VERSION"HIPBNYYYYYYYYYYYYYYYYYYYYYYYYYYYNNNNNNNNNN/4/%%%/4/'%**4NNN///"

NS_ :

BS_:

BU_: RTRange

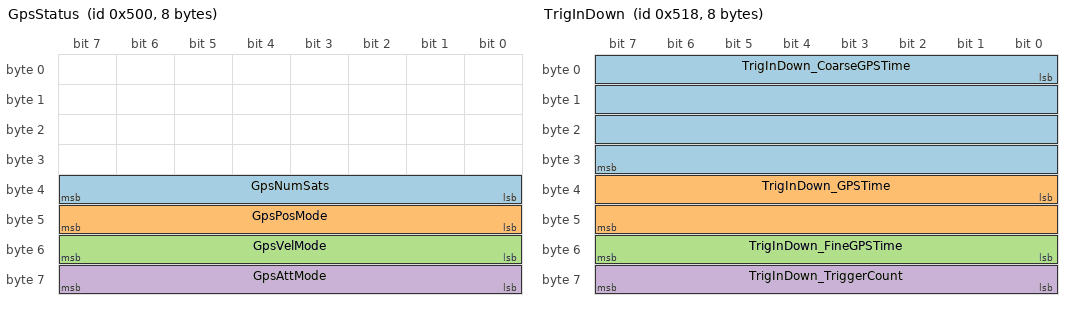
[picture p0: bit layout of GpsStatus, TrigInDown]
BO_ 1280 GpsStatus: 8  RT3000
 SG_ GpsNumSats : 32|8@1+ (1,0) [0|0] "" Vector__XXX
 SG_ GpsPosMode : 40|8@1+ (1,0) [0|0] "" Vector__XXX
 SG_ GpsVelMode : 48|8@1+ (1,0) [0|0] "" Vector__XXX
 SG_ GpsAttMode : 56|8@1+ (1,0) [0|0] "" Vector__XXX

BO_ 1283 PosNEDStdev: 8  RT3000
 SG_ PosNorthStdev : 0|16@1+ (0.001,0) [0|65.535] "m" Vector__XXX
 SG_ PosEastStdev : 16|16@1+ (0.001,0) [0|65.535] "m" Vector__XXX
 SG_ PosDownStdev : 32|16@1+ (0.001,0) [0|65.535] "m" Vector__XXX

BO_ 1284 VelNEDStdev: 8  RT3000
 SG_ VelNorthStdev : 0|16@1+ (0.001,0) [0|65.535] "m/s" Vector__XXX
 SG_ VelEastStdev : 16|16@1+ (0.001,0) [0|65.535] "m/s" Vector__XXX
 SG_ VelDownStdev : 32|16@1+ (0.001,0) [0|65.535] "m/s" Vector__XXX

BO_ 1285 AngleStdev: 8  RT3000
 SG_ AngleHeadingStdev : 0|16@1+ (0.0005729577951,0) [0|37.548789102] "°" Vector__XXX
 SG_ AnglePitchStdev : 16|16@1+ (0.0005729577951,0) [0|37.548789102] "°" Vector__XXX
 SG_ AngleRollStdev : 32|16@1+ (0.0005729577951,0) [0|37.548789102] "°" Vector__XXX

BO_ 1286 GyroBias: 8  RT3000
 SG_ GyroBias1 : 0|16@1- (0.0002864788976,0) [-9.387340515|9.387054037] "°" Vector__XXX
 SG_ GyroBias2 : 16|16@1- (0.0002864788976,0) [-9.387340515|9.387054037] "°" Vector__XXX
 SG_ GyroBias3 : 32|16@1- (0.0002864788976,0) [-9.387340515|9.387054037] "°" Vector__XXX

BO_ 1287 AccelBias: 8  RT3000
 SG_ AccelBias1 : 0|16@1- (0.0001,0) [-3.2768|3.2767] "m/s²" Vector__XXX
 SG_ AccelBias2 : 16|16@1- (0.0001,0) [-3.2768|3.2767] "m/s²" Vector__XXX
 SG_ AccelBias3 : 32|16@1- (0.0001,0) [-3.2768|3.2767] "m/s²" Vector__XXX

BO_ 1288 GyroSf: 8  RT3000
 SG_ GyroSf1 : 0|16@1- (1,0) [-32768|32767] "ppm" Vector__XXX
 SG_ GyroSf2 : 16|16@1- (1,0) [-32768|32767] "ppm" Vector__XXX
 SG_ GyroSf3 : 32|16@1- (1,0) [-32768|32767] "ppm" Vector__XXX

BO_ 1289 GyroBiasStdev: 8  RT3000
 SG_ GyroBias1Stdev  : 0|16@1+ (5.729577951E-005,0) [0|3.7548789102] "°/s" Vector__XXX
 SG_ GyroBias2Stdev  : 16|16@1+ (5.729577951E-005,0) [0|3.7548789102] "°/s" Vector__XXX
 SG_ GyroBias3Stdev  : 32|16@1+ (5.729577951E-005,0) [0|3.7548789102] "°/s" Vector__XXX

BO_ 1290 AccelBiasStdev: 8  RT3000
 SG_ AccelBias1Stdev : 0|16@1+ (1E-005,0) [0|0.65535] "m/s²" Vector__XXX
 SG_ AccelBias2Stdev : 16|16@1+ (1E-005,0) [0|0.65535] "m/s²" Vector__XXX
 SG_ AccelBias3Stdev : 32|16@1+ (1E-005,0) [0|0.65535] "m/s²" Vector__XXX

BO_ 1291 GyroSfStdev: 8  RT3000
 SG_ GyroSf1Stdev : 0|16@1+ (1,0) [0|65535] "ppm" Vector__XXX
 SG_ GyroSf2Stdev : 16|16@1+ (1,0) [0|65535] "ppm" Vector__XXX
 SG_ GyroSf3Stdev : 32|16@1+ (1,0) [0|65535] "ppm" Vector__XXX

BO_ 1292 GpsAntOffset: 8  RT3000
 SG_ GpsAntX : 0|16@1- (0.001,0) [-32.768|32.767] "m" Vector__XXX
 SG_ GpsAntY : 16|16@1- (0.001,0) [-32.768|32.767] "m" Vector__XXX
 SG_ GpsAntZ : 32|16@1- (0.001,0) [-32.768|32.767] "m" Vector__XXX

BO_ 1293 GpsAntAngles: 8  RT3000
 SG_ GpsAntHeading : 0|16@1- (0.005729578,0) [-187.7468103084|187.741080735] "°" Vector__XXX
 SG_ GpsAntPitch : 16|16@1- (0.005729578,0) [-187.7468103084|187.741080735] "°" Vector__XXX

BO_ 1294 GPSAntStdev: 8  RT3000
 SG_ GpsAntXStdev  : 0|16@1+ (0.0001,0) [0|6.5535] "m" Vector__XXX
 SG_ GpsAntYStdev  : 16|16@1+ (0.0001,0) [0|6.5535] "m" Vector__XXX
 SG_ GpsAntZStdev  : 32|16@1+ (0.0001,0) [0|6.5535] "m" Vector__XXX

BO_ 1295 GPSAntAngleStdev: 8  RT3000
 SG_ GpsAntHeadingStdev : 0|16@1+ (0.0005729577951,0) [0|37.548789102] "°" Vector__XXX
 SG_ GpsAntPitchStdev : 16|16@1+ (0.0005729577951,0) [0|37.548789102] "°" Vector__XXX

BO_ 1300 GpsDiffAge: 8  RT3000
 SG_ GpsDiffAge : 0|16@1+ (0.01,0) [0|655.35] "s" Vector__XXX

BO_ 1304 TrigInDown: 8  RT3000
 SG_ TrigInDown_CoarseGPSTime : 0|32@1+ (1,0) [0|4294967296]"minute" Vector__XXX
 SG_ TrigInDown_GPSTime : 32|16@1+ (0.001,0) [0|65.536]"s" Vector__XXX
 SG_ TrigInDown_FineGPSTime : 48|8@1- (0.004,0) [-0.512|0.512]"ms" Vector__XXX
 SG_ TrigInDown_TriggerCount : 56|8@1+ (1,0) [0|256]"" Vector__XXX

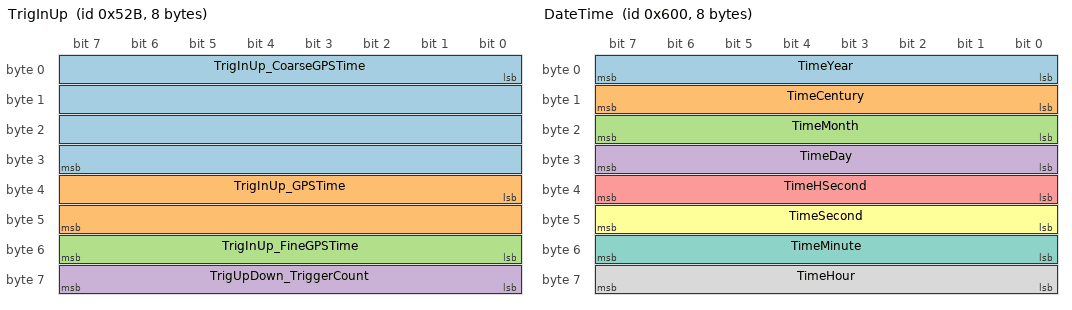
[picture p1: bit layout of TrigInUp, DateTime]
BO_ 1323 TrigInUp: 8  RT3000
 SG_ TrigInUp_CoarseGPSTime : 0|32@1+ (1,0) [0|4294967296]"minute" Vector__XXX
 SG_ TrigInUp_GPSTime : 32|16@1+ (0.001,0) [0|65.536]"s" Vector__XXX
 SG_ TrigInUp_FineGPSTime : 48|8@1- (0.004,0) [-0.512|0.512]"ms" Vector__XXX
 SG_ TrigUpDown_TriggerCount : 56|8@1+ (1,0) [0|256]"" Vector__XXX

BO_ 1325 WheelSpeedStatus: 8  RT3000
 SG_ WSpeedCount : 0|32@1+ (1,0) [0|4294967296] "" Vector__XXX
 SG_ WSpeedGPSTime : 32|16@1+ (0.001,0) [0|65.536]"s" Vector__XXX
 SG_ WSpeedChangeTime : 48|8@1+ (0.1,0) [0|25.6]"s" Vector__XXX

BO_ 1328 UndulationDOP: 8  RT3000
 SG_ Undulation : 0|16@1- (0.005,0) [-163.84|163.835] "m" Vector__XXX
 SG_ HDOP : 16|8@1+ (0.1,0) [0|25.5] "" Vector__XXX
 SG_ PDOP : 24|8@1+ (0.1,0) [0|25.5] "" Vector__XXX

BO_ 1329 OmniStarTracking: 8  RT3000
 SG_ OmniSatFreq : 0|16@1+ (0.001,1520) [1520|1585.535] "MHz" Vector__XXX
 SG_ OmniSNR : 16|8@1+ (0.2,0) [0|51] "dB" Vector__XXX
 SG_ OmniTrackTime : 24|8@1+ (1,0) [0|255] "s" Vector__XXX

BO_ 1343 AngAccFilt: 8  RT3000

BO_ 1536 DateTime: 8  RT3000
 SG_ TimeYear : 0|8@1+ (1,0) [0|100] "" Vector__XXX
 SG_ TimeCentury : 8|8@1+ (1,0) [0|0] "" Vector__XXX
 SG_ TimeMonth : 16|8@1+ (1,0) [0|12] "" Vector__XXX
 SG_ TimeDay : 24|8@1+ (1,0) [0|31] "" Vector__XXX
 SG_ TimeHSecond : 32|8@1+ (0.01,0) [0|1.00] "s" Vector__XXX
 SG_ TimeSecond : 40|8@1+ (1,0) [0|60] "s" Vector__XXX
 SG_ TimeMinute : 48|8@1+ (1,0) [0|60] "min" Vector__XXX
 SG_ TimeHour : 56|8@1+ (1,0) [0|24] "hr" Vector__XXX

BO_ 1537 LatitudeLongitude: 8  RT3000
 SG_ PosLat : 0|32@1- (1E-007,0) [-214.7483648|214.7483647] "°" Vector__XXX
 SG_ PosLon : 32|32@1- (1E-007,0) [-214.7483648|214.7483647] "°" Vector__XXX

BO_ 1538 Altitude: 4  RT3000
 SG_ PosAlt : 0|32@1- (0.001,0) [-2147483.648|2147483.647] "m" Vector__XXX

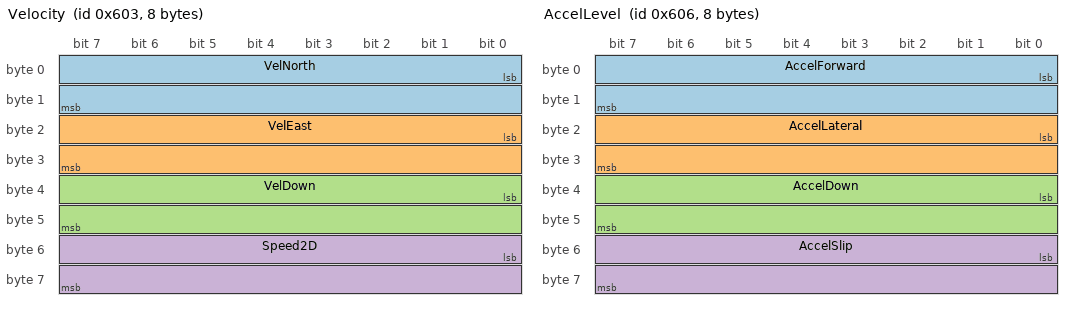
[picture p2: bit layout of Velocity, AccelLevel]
BO_ 1539 Velocity: 8  RT3000
 SG_ VelNorth : 0|16@1- (0.01,0) [-327.68|327.67] "m/s" Vector__XXX
 SG_ VelEast : 16|16@1- (0.01,0) [-327.68|327.67] "m/s" Vector__XXX
 SG_ VelDown : 32|16@1- (0.01,0) [-327.68|327.67] "m/s" Vector__XXX
 SG_ Speed2D : 48|16@1+ (0.01,0) [0|655.35] "m/s" Vector__XXX

BO_ 1540 VelocityLevel: 4  RT3000
 SG_ VelForward : 0|16@1- (0.01,0) [-327.68|327.67] "m/s" Vector__XXX
 SG_ VelLateral : 16|16@1- (0.01,0) [-327.68|327.67] "m/s" Vector__XXX

BO_ 1541 AccelVehicle: 6  RT3000
 SG_ AccelX : 0|16@1- (0.01,0) [-327.68|327.67] "m/s²" Vector__XXX
 SG_ AccelY : 16|16@1- (0.01,0) [-327.68|327.67] "m/s²" Vector__XXX
 SG_ AccelZ : 32|16@1- (0.01,0) [-327.68|327.67] "m/s²" Vector__XXX

BO_ 1542 AccelLevel: 8  RT3000
 SG_ AccelForward : 0|16@1- (0.01,0) [-327.68|327.67] "m/s²" Vector__XXX
 SG_ AccelLateral : 16|16@1- (0.01,0) [-327.68|327.67] "m/s²" Vector__XXX
 SG_ AccelDown : 32|16@1- (0.01,0) [-327.68|327.67] "m/s²" Vector__XXX
 SG_ AccelSlip : 48|16@1- (0.01,0) [-327.68|327.67] "m/s²" Vector__XXX

BO_ 1543 HeadingPitchRoll: 6  RT3000
 SG_ AngleHeading : 0|16@1+ (0.01,0) [0|655.35] "°" Vector__XXX
 SG_ AnglePitch : 16|16@1- (0.01,0) [-327.68|327.67] "°" Vector__XXX
 SG_ AngleRoll : 32|16@1- (0.01,0) [-327.68|327.67] "°" Vector__XXX

BO_ 1544 RateVehicle: 6  RT3000
 SG_ AngRateX : 0|16@1- (0.01,0) [-327.68|327.67] "°/s" Vector__XXX
 SG_ AngRateY : 16|16@1- (0.01,0) [-327.68|327.67] "°/s" Vector__XXX
 SG_ AngRateZ : 32|16@1- (0.01,0) [-327.68|327.67] "°/s" Vector__XXX

BO_ 1545 RateLevel: 6  RT3000
 SG_ AngRateForward : 0|16@1- (0.01,0) [-327.68|327.67] "°/s" Vector__XXX
 SG_ AngRateLateral : 16|16@1- (0.01,0) [-327.68|327.67] "°/s" Vector__XXX
 SG_ AngRateDown : 32|16@1- (0.01,0) [-327.68|327.67] "°/s" Vector__XXX

BO_ 1546 TrackSlipCurvature: 6  RT3000
 SG_ AngleTrack : 0|16@1+ (0.01,0) [0|655.35] "°" Vector__XXX
 SG_ AngleSlip : 16|16@1- (0.01,0) [-327.68|327.67] "°" Vector__XXX
 SG_ Curvature : 32|16@1- (0.0001,0) [-3.2768|3.2767] "1/m" Vector__XXX

BO_ 1547 Distance: 8  RT3000
 SG_ DistanceWithHold : 0|32@1+ (0.001,0) [0|4294967.295] "m" Vector__XXX
 SG_ Distance : 32|32@1+ (0.001,0) [0|4294967.295] "m" Vector__XXX

BO_ 1548 PosLocal: 8  RT3000
 SG_ PosLocalX : 0|32@1- (0.0001,0) [-214748.3648|214748.3647] "m" Vector__XXX
 SG_ PosLocalY : 32|32@1- (0.0001,0) [-214748.3648|214748.3647] "m" Vector__XXX

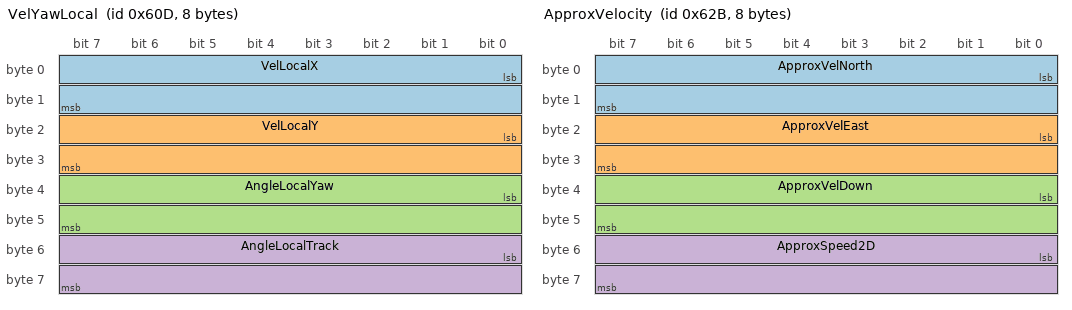
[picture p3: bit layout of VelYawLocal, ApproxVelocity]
BO_ 1549 VelYawLocal: 8  RT3000
 SG_ VelLocalX : 0|16@1- (0.01,0) [-327.68|327.67] "m/s" Vector__XXX
 SG_ VelLocalY : 16|16@1- (0.01,0) [-327.68|327.67] "m/s" Vector__XXX
 SG_ AngleLocalYaw : 32|16@1- (0.01,0) [-327.68|327.67] "°" Vector__XXX
 SG_ AngleLocalTrack : 48|16@1- (0.01,0) [-327.68|327.67] "°" Vector__XXX

BO_ 1550 AngAccelVehicle: 6  RT3000
 SG_ AngAccelX : 0|16@1- (0.1,0) [-3276.8|3276.7] "°/s²" Vector__XXX
 SG_ AngAccelY : 16|16@1- (0.1,0) [-3276.8|3276.7] "°/s²" Vector__XXX
 SG_ AngAccelZ : 32|16@1- (0.1,0) [-3276.8|3276.7] "°/s²" Vector__XXX

BO_ 1551 AngAccelLevel: 6  RT3000
 SG_ AngAccelForward : 0|16@1- (0.1,0) [-3276.8|3276.7] "°/s²" Vector__XXX
 SG_ AngAccelLateral : 16|16@1- (0.1,0) [-3276.8|3276.7] "°/s²" Vector__XXX
 SG_ AngAccelDown : 32|16@1- (0.1,0) [-3276.8|3276.7] "°/s²" Vector__XXX

BO_ 1568 TrackSlipCurvaturePoint1: 8  RT3000
 SG_ AngleTrackPoint1 : 0|16@1+ (0.01,0) [0|655.35] "°" Vector__XXX
 SG_ AngleSlipPoint1 : 16|16@1- (0.01,0) [-327.68|327.67] "°" Vector__XXX
 SG_ CurvaturePoint1 : 32|16@1- (0.0001,0) [-3.2768|3.2767] "1/m" Vector__XXX

BO_ 1569 TrackSlipCurvaturePoint2: 8  RT3000
 SG_ AngleTrackPoint2 : 0|16@1+ (0.01,0) [0|655.35] "°" Vector__XXX
 SG_ AngleSlipPoint2 : 16|16@1- (0.01,0) [-327.68|327.67] "°" Vector__XXX
 SG_ CurvaturePoint2 : 32|16@1- (0.0001,0) [-3.2768|3.2767] "1/m" Vector__XXX

BO_ 1570 TrackSlipCurvaturePoint3: 8  RT3000
 SG_ AngleTrackPoint3 : 0|16@1+ (0.01,0) [0|655.35] "°" Vector__XXX
 SG_ AngleSlipPoint3 : 16|16@1- (0.01,0) [-327.68|327.67] "°" Vector__XXX
 SG_ CurvaturePoint3 : 32|16@1- (0.0001,0) [-3.2768|3.2767] "1/m" Vector__XXX

BO_ 1571 TrackSlipCurvaturePoint4: 8  RT3000
 SG_ AngleTrackPoint4 : 0|16@1+ (0.01,0) [0|655.35] "°" Vector__XXX
 SG_ AngleSlipPoint4 : 16|16@1- (0.01,0) [-327.68|327.67] "°" Vector__XXX
 SG_ CurvaturePoint4 : 32|16@1- (0.0001,0) [-3.2768|3.2767] "1/m" Vector__XXX

BO_ 1572 HeadingPitchRollFromSurf: 6  RT3000
 SG_ AngleHeadingFromSurf : 0|16@1+ (0.01,0) [0|655.35] "°" Vector__XXX
 SG_ AnglePitchFromSurf : 16|16@1- (0.01,0) [-327.68|327.67] "°" Vector__XXX
 SG_ AngleRollFromSurf : 32|16@1- (0.01,0) [-327.68|327.67] "°" Vector__XXX

BO_ 1573 TrackSlipCurvaturePoint5: 8  RT3000
 SG_ AngleTrackPoint5 : 0|16@1+ (0.01,0) [0|655.35] "°" Vector__XXX
 SG_ AngleSlipPoint5 : 16|16@1- (0.01,0) [-327.68|327.67] "°" Vector__XXX
 SG_ CurvaturePoint5 : 32|16@1- (0.0001,0) [-3.2768|3.2767] "1/m" Vector__XXX

BO_ 1574 TrackSlipCurvaturePoint6: 8  RT3000
 SG_ AngleTrackPoint6 : 0|16@1+ (0.01,0) [0|655.35] "°" Vector__XXX
 SG_ AngleSlipPoint6 : 16|16@1- (0.01,0) [-327.68|327.67] "°" Vector__XXX
 SG_ CurvaturePoint6 : 32|16@1- (0.0001,0) [-3.2768|3.2767] "1/m" Vector__XXX

BO_ 1575 TrackSlipCurvaturePoint7: 8  RT3000
 SG_ AngleTrackPoint7 : 0|16@1+ (0.01,0) [0|655.35] "°" Vector__XXX
 SG_ AngleSlipPoint7 : 16|16@1- (0.01,0) [-327.68|327.67] "°" Vector__XXX
 SG_ CurvaturePoint7 : 32|16@1- (0.0001,0) [-3.2768|3.2767] "1/m" Vector__XXX

BO_ 1576 TrackSlipCurvaturePoint8: 8  RT3000
 SG_ AngleTrackPoint8 : 0|16@1+ (0.01,0) [0|655.35] "°" Vector__XXX
 SG_ AngleSlipPoint8 : 16|16@1- (0.01,0) [-327.68|327.67] "°" Vector__XXX
 SG_ CurvaturePoint8 : 32|16@1- (0.0001,0) [-3.2768|3.2767] "1/m" Vector__XXX

BO_ 1577 ApproxLatitudeLongitude: 8  RT3000
 SG_ ApproxPosLat : 0|32@1- (1E-007,0) [-214.7483648|214.7483647] "°" Vector__XXX
 SG_ ApproxPosLon : 32|32@1- (1E-007,0) [-214.7483648|214.7483647] "°" Vector__XXX

BO_ 1578 ApproxAltitude: 4  RT3000
 SG_ ApproxPosAlt : 0|32@1- (0.001,0) [-2147483.648|2147483.647] "m" Vector__XXX

BO_ 1579 ApproxVelocity: 8  RT3000
 SG_ ApproxVelNorth : 0|16@1- (0.01,0) [-327.68|327.67] "m/s" Vector__XXX
 SG_ ApproxVelEast : 16|16@1- (0.01,0) [-327.68|327.67] "m/s" Vector__XXX
 SG_ ApproxVelDown : 32|16@1- (0.01,0) [-327.68|327.67] "m/s" Vector__XXX
 SG_ ApproxSpeed2D : 48|16@1+ (0.01,0) [0|655.35] "m/s" Vector__XXX

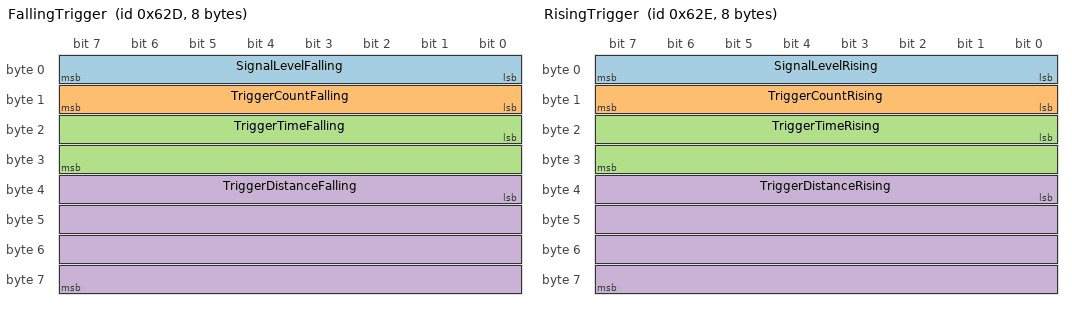
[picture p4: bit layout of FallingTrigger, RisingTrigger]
BO_ 1581 FallingTrigger: 8  RT3000
 SG_ SignalLevelFalling : 0|8 @1+ (1,0) [0|255] "" Vector__XXX
 SG_ TriggerCountFalling : 8|8 @1+ (1,0) [0|255] "" Vector__XXX
 SG_ TriggerTimeFalling : 16|16 @1+ (0.0002,0) [0|13.1072] "s" Vector__XXX
 SG_ TriggerDistanceFalling : 32|32 @1+ (0.001,0) [0|4294967.295] "m" Vector__XXX

BO_ 1582 RisingTrigger: 8  RT3000
 SG_ SignalLevelRising : 0|8 @1+ (1,0) [0|255] "" Vector__XXX
 SG_ TriggerCountRising : 8|8 @1+ (1,0) [0|255] "" Vector__XXX
 SG_ TriggerTimeRising : 16|16 @1+ (0.0002,0) [0|13.1072] "s" Vector__XXX
 SG_ TriggerDistanceRising : 32|32 @1+ (0.001,0) [0|4294967.295] "m" Vector__XXX

BO_ 1968  RangeForward: 8 RTRange
SG_ RangePosForward:                 0|32@1-  (0.001,0)  [-2147483.6475|2147483.6475]"m" Vector__XXX
SG_ RangeVelForward:                 32|16@1-  (0.01,0)  [-327.675|327.675]"m/s" Vector__XXX
SG_ RangeTimeToCollisionForward :    48|16@1-  (0.001,0)  [-32.7675|32.7675]"s" Vector__XXX

BO_ 1969 RangeLateral: 8 RTRange
SG_ RangePosLateral:             0|32@1-  (0.001,0)  [-2147483.6475|2147483.6475]"m" Vector__XXX
SG_ RangeVelLateral:             32|16@1-  (0.01,0)  [-327.675|327.675]"m/s" Vector__XXX
SG_ RangeTimeToCollisionLateral: 48|16@1-  (0.001,0)  [-32.7675|32.7675]"s" Vector__XXX

BO_ 1970 RangeResultant: 8 RTRange
SG_ RangePosRes:         0|32@1-  (0.001,0)  [-2147483.6475|2147483.6475]"m" Vector__XXX
SG_ RangeVelRes:         32|16@1-  (0.01,0)  [-327.675|327.675]"m/s" Vector__XXX
SG_ RangeAngleHeading:   48|16@1-  (0.01,0)  [-327.675|327.675]"°" Vector__XXX

BO_ 1971 RangeHunterPosLocal: 8 RTRange
SG_ RangeHunterPosLocalX : 0|32@1-  (0.001,0)  [-2147483.6475|2147483.6475]"m" Vector__XXX
SG_ RangeHunterPosLocalY : 32|32@1-  (0.001,0)  [-2147483.6475|2147483.6475]"m" Vector__XXX

BO_ 1972 RangeTargetPosLocal: 8 RTRange
SG_ RangeTargetPosLocalX : 0|32@1-  (0.001,0)  [-2147483.6475|2147483.6475]"m" Vector__XXX
SG_ RangeTargetPosLocalY : 32|32@1-  (0.001,0)  [-2147483.6475|2147483.6475]"m" Vector__XXX

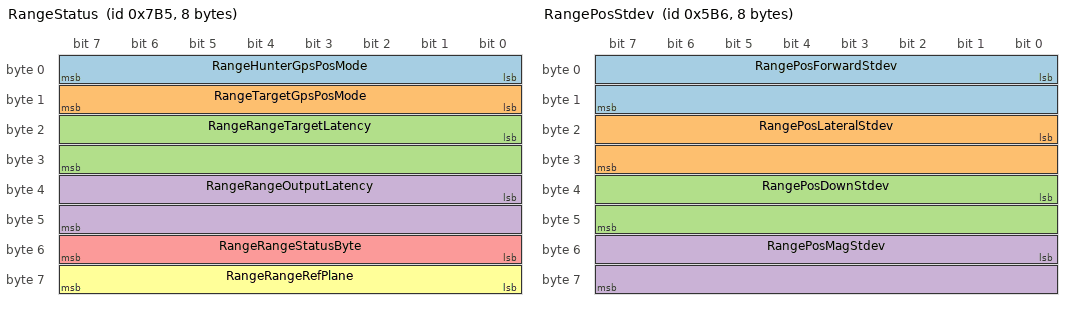
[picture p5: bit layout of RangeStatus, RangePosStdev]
BO_ 1973 RangeStatus: 8 RTRange
SG_ RangeHunterGpsPosMode:   0|8@1+  (1,0)  [0|255]"" Vector__XXX
SG_ RangeTargetGpsPosMode:   8|8@1+  (1,0)  [0|255]"" Vector__XXX
SG_ RangeRangeTargetLatency: 16|16@1+  (0.001,0)  [0|65.535]"s" Vector__XXX
SG_ RangeRangeOutputLatency: 32|16@1+  (0.001,0)  [0|65.535]"s" Vector__XXX
SG_ RangeRangeStatusByte:    48|8@1+  (1,0)  [0|255]"" Vector__XXX
SG_ RangeRangeRefPlane:      56|8@1+  (1,0)  [0|255]"" Vector__XXX

BO_ 1974 RangeTimeGap: 4 RTRange
SG_ RangeTimeGap:                     0|16@1-  (0.001,0)  [-32.7675|32.7675]"s" Vector__XXX
SG_ RangeTimeToCollisionForwardWithAccel:    16|16@1-  (0.001,0)  [-32.7675|32.7675]"s" Vector__XXX

BO_ 1975 RangeLocal: 8 RTRange
SG_ RangeLocalDeltaX : 0|32@1-  (0.001,0)  [-2147483.6475|2147483.6475]"m" Vector__XXX
SG_ RangeLocalDeltaY : 32|32@1-  (0.001,0)  [-2147483.6475|2147483.6475]"m" Vector__XXX

BO_ 1976 RangePolygon: 4 RTRange
SG_ RangePolygonVisible      : 0|8@1+  (1,0)  [0|255]"" Vector__XXX
SG_ RangePolygonInside       : 8|8@1+  (1,0)  [0|255]"" Vector__XXX
SG_ RangePolygonLeftPoint    : 16|8@1+  (1,0)  [0|255]"" Vector__XXX
SG_ RangePolygonRightPoint   : 24|8@1+  (1,0)  [0|255]"" Vector__XXX

BO_ 1977RangeFeatInfo: 4 RTRange
SG_ RangeFeatID      : 0|16@1+  (1,0)  [0|65535]"" Vector__XXX
SG_ RangeFeatType    : 16|8@1+  (1,0)  [0|255]"" Vector__XXX

BO_ 1456 RangeOffset: 8 RTRange
SG_ RangeOffsetForward:  0|16@1+  (0.001,0)  [0|65.535]"m" Vector__XXX
SG_ RangeOffsetLateral: 16|16@1+  (0.001,0)  [0|65.535]"m" Vector__XXX

BO_ 1457 RangeFixedPointLL: 8 RTRange
SG_ RangeFixedPointLat:  0|32@1-  (1E-07,0)  [-214.74836475|214.74836475]"m" Vector__XXX
SG_ RangeFixedPointLon:  32|32@1-  (1E-07,0)  [-214.74836475|214.74836475]"m" Vector__XXX

BO_ 1458 RangeFixedPointHH: 8 RTRange
SG_ RangeFixedPointAlt:  0|32@1-  (0.001,0)  [-2147483.6475|2147483.6475]"m" Vector__XXX
SG_ RangeFixedPointHea:  32|16@1+  (0.01,0)  [0|655.35]"m" Vector__XXX

BO_ 1459 RangeSensorLeverArm: 8 RTRange
SG_ RangeSensorLeverArmX: 0|16@1-  (0.001,0)  [-32.7675|32.7675]"m" Vector__XXX
SG_ RangeSensorLeverArmY: 16|16@1-  (0.001,0)  [-32.7675|32.7675]"m" Vector__XXX
SG_ RangeSensorLeverArmZ: 32|16@1-  (0.001,0)  [-32.7675|32.7675]"m" Vector__XXX

BO_ 1460 RangeBullsEyeLeverArm: 8 RTRange
SG_ RangeBullsEyeLeverArmX: 0|16@1-  (0.001,0)  [-32.7675|32.7675]"m" Vector__XXX
SG_ RangeBullsEyeLeverArmY: 16|16@1-  (0.001,0)  [-32.7675|32.7675]"m" Vector__XXX
SG_ RangeBullsEyeLeverArmZ: 32|16@1-  (0.001,0)  [-32.7675|32.7675]"m" Vector__XXX

BO_ 1461 RangeVehicle: 8 RTRange
SG_ RangeTargetVehicleLength: 0|16@1+  (0.001,0)  [0|65.535]"m" Vector__XXX
SG_ RangeTargetVehicleWidth: 16|16@1+  (0.001,0)  [0|65.535]"m" Vector__XXX
SG_ RangeTargetPolygonNumber: 32|16@1+  (1,0)  [0|65535]"" Vector__XXX

BO_ 1462 RangePosStdev: 8 RTRange
SG_ RangePosForwardStdev: 0|16@1+  (0.001,0)  [0|65.535]"m" Vector__XXX
SG_ RangePosLateralStdev: 16|16@1+  (0.001,0)  [0|65.535]"m" Vector__XXX
SG_ RangePosDownStdev:    32|16@1+  (0.001,0)  [0|65.535]"m" Vector__XXX
SG_ RangePosMagStdev:     48|16@1+  (0.001,0)  [0|65.535]"m" Vector__XXX

BO_ 1463 RangeFeatPointLL: 8 RTRange
SG_ RangeFeatPointLat: 0|32@1-  (1E-07,0)  [-214.74836475|214.74836475]"°" Vector__XXX
SG_ RangeFeatPointLon: 32|32@1-  (1E-07,0)  [-214.74836475|214.74836475]"°" Vector__XXX

BO_ 1464 RangeFeatPointHH: 8 RTRange
SG_ RangeFeatPointAlt: 0|32@1-  (0.001,0)  [-2147483.6475|2147483.6475]"m" Vector__XXX
SG_ RangeFeatPointHea: 32|16@1+  (0.01,0)  [0|655.35]"°" Vector__XXX

BO_ 1952 LaneMapStatus: 8 RTRange
SG_ RefLineDistAlong:    0|32@1-  (0.001,0)  [-2147483.6475|2147483.6475]"m" Vector__XXX
SG_ MapNumber:           32|8@1+  (1,0)  [0|255]"" Vector__XXX

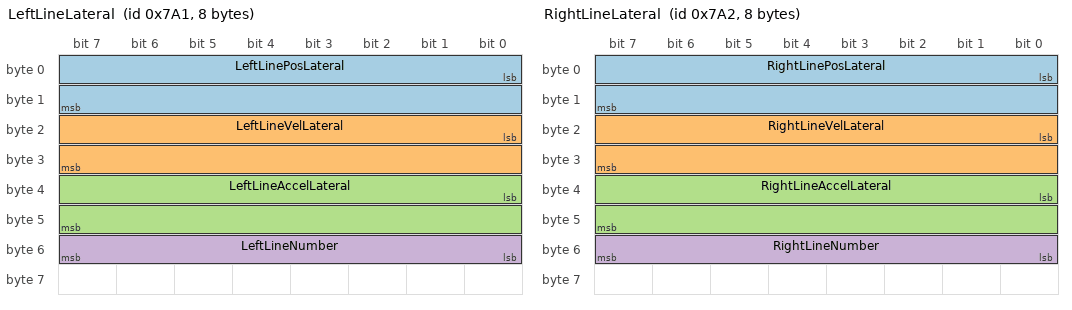
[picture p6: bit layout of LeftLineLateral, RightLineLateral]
BO_ 1953 LeftLineLateral: 8 RTRange
SG_ LeftLinePosLateral:      0|16@1-  (0.001,0)  [-32.7675|32.7675]"m" Vector__XXX
SG_ LeftLineVelLateral:      16|16@1-  (0.01,0)  [-327.675|327.675]"m/s" Vector__XXX
SG_ LeftLineAccelLateral:    32|16@1-  (0.01,0)  [-327.675|327.675]"m/s²" Vector__XXX
SG_ LeftLineNumber:          48|8@1+  (1,0)  [0|255]"" Vector__XXX

BO_ 1954 RightLineLateral: 8 RTRange
SG_ RightLinePosLateral:     0|16@1-  (0.001,0)  [-32.7675|32.7675]"m" Vector__XXX
SG_ RightLineVelLateral:     16|16@1-  (0.01,0)  [-327.675|327.675]"m/s" Vector__XXX
SG_ RightLineAccelLateral:   32|16@1-  (0.01,0)  [-327.675|327.675]"m/s²" Vector__XXX
SG_ RightLineNumber:         48|8@1+  (1,0)  [0|255]"" Vector__XXX

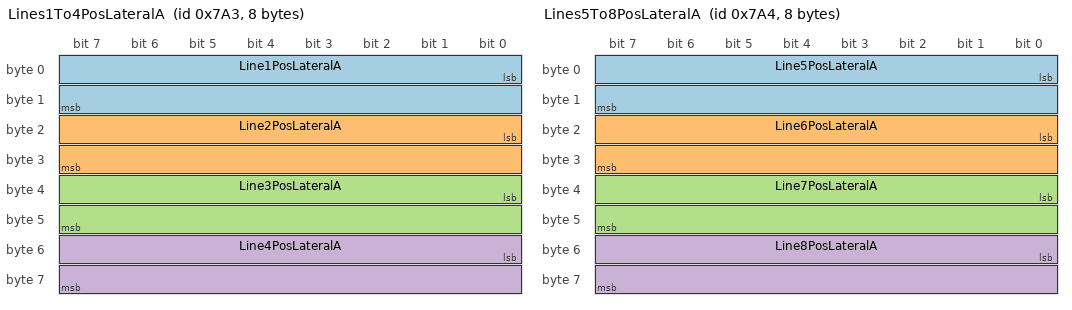
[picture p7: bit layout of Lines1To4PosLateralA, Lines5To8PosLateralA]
BO_ 1955 Lines1To4PosLateralA: 8 RTRange
SG_ Line1PosLateralA: 0|16@1-  (0.001,0)  [-32.7675|32.7675]"m" Vector__XXX
SG_ Line2PosLateralA: 16|16@1-  (0.001,0)  [-32.7675|32.7675]"m" Vector__XXX
SG_ Line3PosLateralA: 32|16@1-  (0.001,0)  [-32.7675|32.7675]"m" Vector__XXX
SG_ Line4PosLateralA: 48|16@1-  (0.001,0)  [-32.7675|32.7675]"m" Vector__XXX

BO_ 1956 Lines5To8PosLateralA: 8 RTRange
SG_ Line5PosLateralA: 0|16@1-  (0.001,0)  [-32.7675|32.7675]"m" Vector__XXX
SG_ Line6PosLateralA: 16|16@1-  (0.001,0)  [-32.7675|32.7675]"m" Vector__XXX
SG_ Line7PosLateralA: 32|16@1-  (0.001,0)  [-32.7675|32.7675]"m" Vector__XXX
SG_ Line8PosLateralA: 48|16@1-  (0.001,0)  [-32.7675|32.7675]"m" Vector__XXX

BO_ 1957 LinesFromB: 4 RTRange
SG_ LeftFromBPosLateral: 0|16@1-  (0.001,0)  [-32.7675|32.7675]"m" Vector__XXX
SG_ LeftOfBNumber:       16|8@1+  (1,0)  [0|255]"" Vector__XXX
SG_ RightOfBNumber:      24|8@1+  (1,0)  [0|255]"" Vector__XXX
SG_ CurvatureOfB:        32|16@1-  (0.0001,0)  [-3.27675|3.27675]"1/m" Vector__XXX

BO_ 1958 LinesFromC: 4 RTRange
SG_ RightFromCPosLateral:    0|16@1-  (0.001,0)  [-32.7675|32.7675]"m" Vector__XXX
SG_ LeftOfCNumber:           16|8@1+  (1,0)  [0|255]"" Vector__XXX
SG_ RightOfCNumber:          24|8@1+  (1,0)  [0|255]"" Vector__XXX
SG_ CurvatureOfC:            32|16@1-  (0.0001,0)  [-3.27675|3.27675]"1/m" Vector__XXX

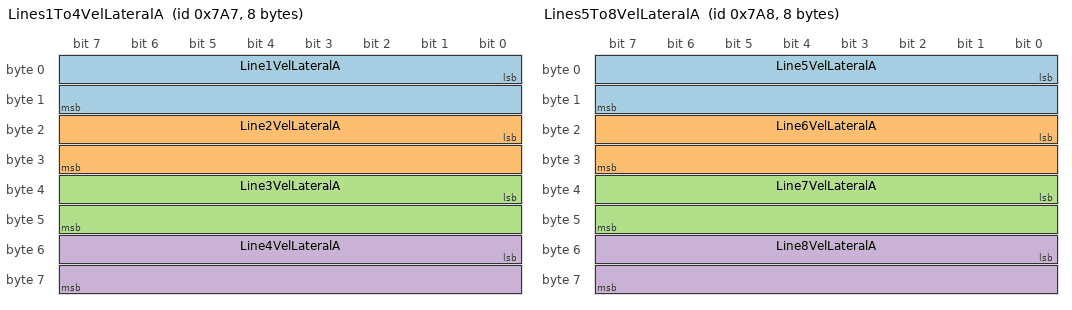
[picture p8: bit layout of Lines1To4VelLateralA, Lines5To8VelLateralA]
BO_ 1959 Lines1To4VelLateralA: 8 RTRange
SG_ Line1VelLateralA: 0|16@1-  (0.01,0)  [-327.675|327.675]"m/s" Vector__XXX
SG_ Line2VelLateralA: 16|16@1-  (0.01,0)  [-327.675|327.675]"m/s" Vector__XXX
SG_ Line3VelLateralA: 32|16@1-  (0.01,0)  [-327.675|327.675]"m/s" Vector__XXX
SG_ Line4VelLateralA: 48|16@1-  (0.01,0)  [-327.675|327.675]"m/s" Vector__XXX

BO_ 1960 Lines5To8VelLateralA: 8 RTRange
SG_ Line5VelLateralA:  0|16@1-  (0.01,0)  [-327.675|327.675]"m/s" Vector__XXX
SG_ Line6VelLateralA:  16|16@1-  (0.01,0)  [-327.675|327.675]"m/s" Vector__XXX
SG_ Line7VelLateralA:  32|16@1-  (0.01,0)  [-327.675|327.675]"m/s" Vector__XXX
SG_ Line8VelLateralA : 48|16@1-  (0.01,0)  [-327.675|327.675]"m/s" Vector__XXX

BO_ 1961 TrajectoryOfA: 8 RTRange
SG_ LeftLineHeadingOfA:      0|16@1-  (0.01,0)  [-327.675|327.675]"°" Vector__XXX
SG_ RightLineHeadingOfA:     16|16@1-  (0.01,0)  [-327.675|327.675]"°" Vector__XXX
SG_ CurvatureOfA:            32|16@1-  (0.0001,0)  [-3.27675|3.27675]"1/m" Vector__XXX

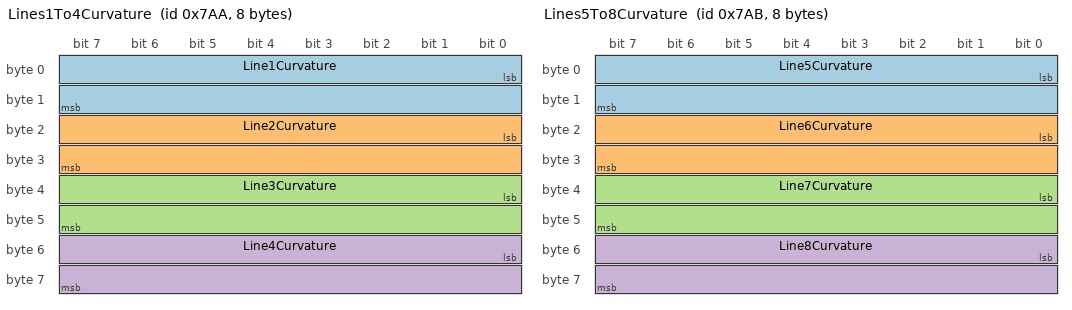
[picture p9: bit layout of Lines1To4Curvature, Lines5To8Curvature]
BO_ 1962 Lines1To4Curvature: 8 RTRange
SG_ Line1Curvature: 0|16@1-  (0.0001,0)  [-3.27675|3.27675]"1/m" Vector__XXX
SG_ Line2Curvature: 16|16@1-  (0.0001,0)  [-3.27675|3.27675]"1/m" Vector__XXX
SG_ Line3Curvature: 32|16@1-  (0.0001,0)  [-3.27675|3.27675]"1/m" Vector__XXX
SG_ Line4Curvature: 48|16@1-  (0.0001,0)  [-3.27675|3.27675]"1/m" Vector__XXX

BO_ 1963 Lines5To8Curvature: 8 RTRange
SG_ Line5Curvature: 0|16@1-  (0.0001,0)  [-3.27675|3.27675]"1/m" Vector__XXX
SG_ Line6Curvature: 16|16@1-  (0.0001,0)  [-3.27675|3.27675]"1/m" Vector__XXX
SG_ Line7Curvature: 32|16@1-  (0.0001,0)  [-3.27675|3.27675]"1/m" Vector__XXX
SG_ Line8Curvature:  48|16@1-  (0.0001,0)  [-3.27675|3.27675]"1/m" Vector__XXX

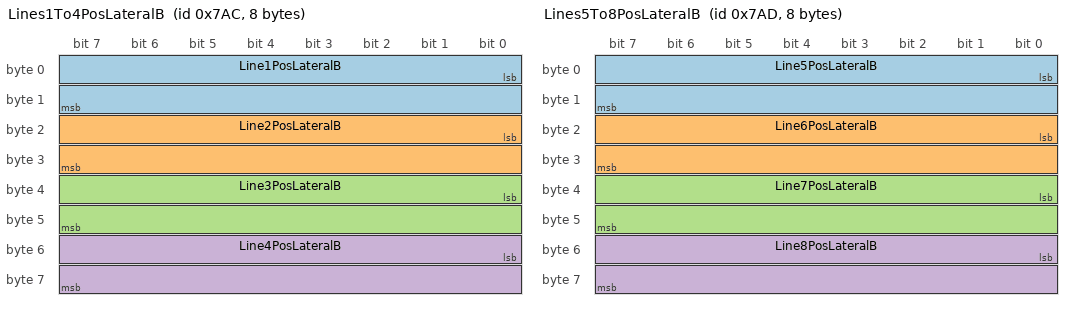
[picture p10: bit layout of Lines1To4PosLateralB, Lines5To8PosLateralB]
BO_ 1964 Lines1To4PosLateralB: 8 RTRange
SG_ Line1PosLateralB: 0|16@1-  (0.001,0)  [-32.7675|32.7675]"m" Vector__XXX
SG_ Line2PosLateralB: 16|16@1-  (0.001,0)  [-32.7675|32.7675]"m" Vector__XXX
SG_ Line3PosLateralB: 32|16@1-  (0.001,0)  [-32.7675|32.7675]"m" Vector__XXX
SG_ Line4PosLateralB:  48|16@1-  (0.001,0)  [-32.7675|32.7675]"m" Vector__XXX

BO_ 1965 Lines5To8PosLateralB: 8 RTRange
SG_ Line5PosLateralB: 0|16@1-  (0.001,0)  [-32.7675|32.7675]"m" Vector__XXX
SG_ Line6PosLateralB: 16|16@1-  (0.001,0)  [-32.7675|32.7675]"m" Vector__XXX
SG_ Line7PosLateralB: 32|16@1-  (0.001,0)  [-32.7675|32.7675]"m" Vector__XXX
SG_ Line8PosLateralB:  48|16@1-  (0.001,0)  [-32.7675|32.7675]"m" Vector__XXX

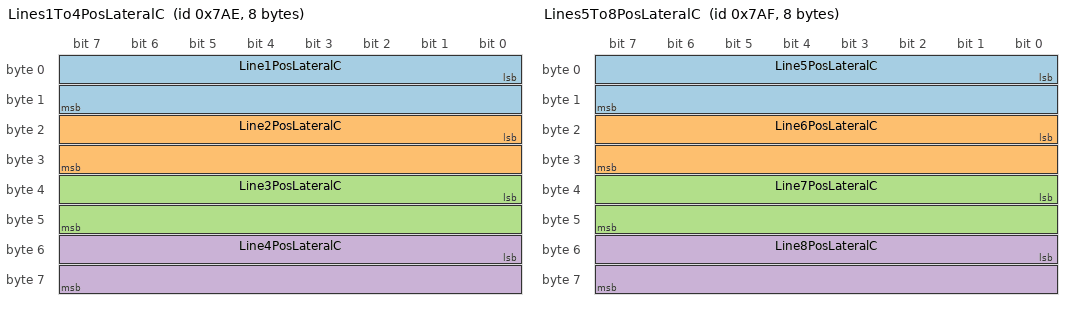
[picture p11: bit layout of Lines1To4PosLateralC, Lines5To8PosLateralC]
BO_ 1966 Lines1To4PosLateralC: 8 RTRange
SG_ Line1PosLateralC: 0|16@1-  (0.001,0)  [-32.7675|32.7675]"m" Vector__XXX
SG_ Line2PosLateralC: 16|16@1-  (0.001,0)  [-32.7675|32.7675]"m" Vector__XXX
SG_ Line3PosLateralC: 32|16@1-  (0.001,0)  [-32.7675|32.7675]"m" Vector__XXX
SG_ Line4PosLateralC: 48|16@1-  (0.001,0)  [-32.7675|32.7675]"m" Vector__XXX

BO_ 1967 Lines5To8PosLateralC: 8 RTRange
SG_ Line5PosLateralC: 0|16@1-  (0.001,0)  [-32.7675|32.7675]"m" Vector__XXX
SG_ Line6PosLateralC: 16|16@1-  (0.001,0)  [-32.7675|32.7675]"m" Vector__XXX
SG_ Line7PosLateralC: 32|16@1-  (0.001,0)  [-32.7675|32.7675]"m" Vector__XXX
SG_ Line8PosLateralC: 48|16@1-  (0.001,0)  [-32.7675|32.7675]"m" Vector__XXX

BO_ 1440 LanePointALeverArm: 8 RTRange
SG_ LanePointALeverArmX: 0|16@1-  (0.001,0)  [-32.7675|32.7675]"m" Vector__XXX
SG_ LanePointALeverArmY: 16|16@1-  (0.001,0)  [-32.7675|32.7675]"m" Vector__XXX
SG_ LanePointALeverArmZ:  32|16@1-  (0.001,0)  [-32.7675|32.7675]"m" Vector__XXX

BO_ 1441 LanePointBLeverArm: 8 RTRange
SG_ LanePointBLeverArmX: 0|16@1-  (0.001,0)  [-32.7675|32.7675]"m" Vector__XXX
SG_ LanePointBLeverArmY: 16|16@1-  (0.001,0)  [-32.7675|32.7675]"m" Vector__XXX
SG_ LanePointBLeverArmZ: 32|16@1-  (0.001,0)  [-32.7675|32.7675]"m" Vector__XXX

BO_ 1442 LanePointCLeverArm: 8 RTRange
SG_ LanePointCLeverArmX: 0|16@1-  (0.001,0)  [-32.7675|32.7675]"m" Vector__XXX
SG_ LanePointCLeverArmY: 16|16@1-  (0.001,0)  [-32.7675|32.7675]"m" Vector__XXX
SG_ LanePointCLeverArmZ: 32|16@1-  (0.001,0)  [-32.7675|32.7675]"m" Vector__XXX

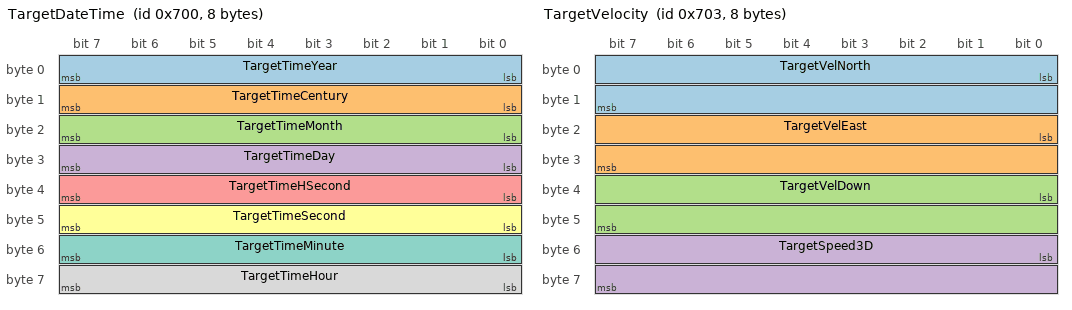
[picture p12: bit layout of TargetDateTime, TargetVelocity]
BO_ 1792 TargetDateTime: 8 RTRange
SG_ TargetTimeYear:      0|8@1+  (1,0)  [0|255]"" Vector__XXX
SG_ TargetTimeCentury:   8|8@1+  (1,0)  [0|255]"" Vector__XXX
SG_ TargetTimeMonth:     16|8@1+  (1,0)  [0|255]"" Vector__XXX
SG_ TargetTimeDay:       24|8@1+  (1,0)  [0|255]"" Vector__XXX
SG_ TargetTimeHSecond:   32|8@1+  (0.01,0)  [0|2.55]"s" Vector__XXX
SG_ TargetTimeSecond:    40|8@1+  (1,0)  [0|255]"s" Vector__XXX
SG_ TargetTimeMinute:    48|8@1+  (1,0)  [0|255]"min" Vector__XXX
SG_ TargetTimeHour:      56|8@1+  (1,0)  [0|255]"hr" Vector__XXX

BO_ 1793 TargetLatitudeLongitude: 8 RTRange
SG_ TargetPosLat: 0|32@1-  (1E-07,0)  [-214.74836475|214.74836475]"°" Vector__XXX
SG_ TargetPosLon: 32|32@1-  (1E-07,0)  [-214.74836475|214.74836475]"°" Vector__XXX

BO_ 1794 TargetAltitude: 4 RTRange
SG_ TargetPosAlt: 0|32@1-  (0.001,0)  [-2147483.6475|2147483.6475]"m" Vector__XXX

BO_ 1795 TargetVelocity: 8 RTRange
SG_ TargetVelNorth: 0|16@1-  (0.01,0)  [-327.675|327.675]"m/s" Vector__XXX
SG_ TargetVelEast: 16|16@1-  (0.01,0)  [-327.675|327.675]"m/s" Vector__XXX
SG_ TargetVelDown: 32|16@1-  (0.01,0)  [-327.675|327.675]"m/s" Vector__XXX
SG_ TargetSpeed3D : 48|16@1+  (0.01,0)  [0|655.35]"m/s" Vector__XXX

BO_ 1796 TargetVelocityLevel: 4 RTRange
SG_ TargetVelForward: 0|16@1-  (0.01,0)  [-327.675|327.675]"m/s" Vector__XXX
SG_ TargetVelLateral: 16|16@1-  (0.01,0)  [-327.675|327.675]"m/s" Vector__XXX

BO_ 1797 TargetAccelVehicle: 6 RTRange
SG_ TargetAccelX : 0|16@1-  (0.01,0)  [-327.675|327.675]"m/s²" Vector__XXX
SG_ TargetAccelY : 16|16@1-  (0.01,0)  [-327.675|327.675]"m/s²" Vector__XXX
SG_ TargetAccelZ : 32|16@1-  (0.01,0)  [-327.675|327.675]"m/s²" Vector__XXX

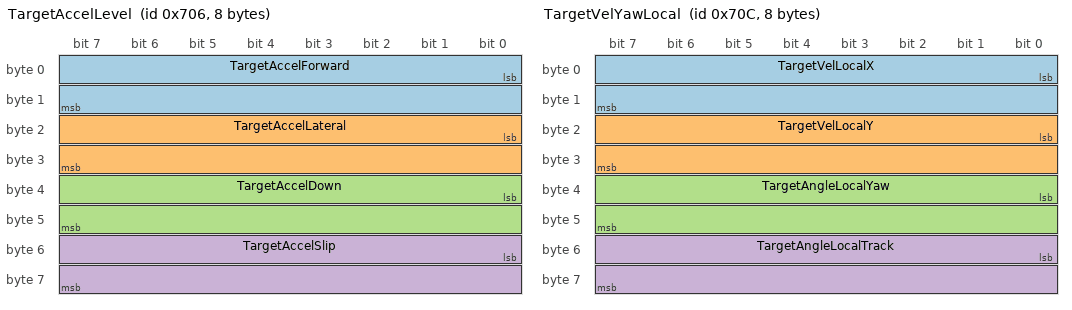
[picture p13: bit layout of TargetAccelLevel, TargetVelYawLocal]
BO_ 1798 TargetAccelLevel: 8 RTRange
SG_ TargetAccelForward:  0|16@1-  (0.01,0)  [-327.675|327.675]"m/s²" Vector__XXX
SG_ TargetAccelLateral:  16|16@1-  (0.01,0)  [-327.675|327.675]"m/s²" Vector__XXX
SG_ TargetAccelDown:     32|16@1-  (0.01,0)  [-327.675|327.675]"m/s²" Vector__XXX
SG_ TargetAccelSlip:     48|16@1-  (0.01,0)  [-327.675|327.675]"m/s²" Vector__XXX

BO_ 1799 TargetHeadingPitchRoll: 6 RTRange
 SG_ TargetAngleHeading: 0|16@1+  (0.01,0)  [0|655.35]"°" Vector__XXX
 SG_ TargetAnglePitch:   16|16@1-  (0.01,0)  [-327.675|327.675]"°" Vector__XXX
 SG_ TargetAngleRoll:    32|16@1-  (0.01,0)  [-327.675|327.675]"°" Vector__XXX

BO_ 1800 TargetRateVehicle: 6 RTRange
SG_ TargetAngRateX : 0|16@1-  (0.01,0)  [-327.675|327.675]"°/s" Vector__XXX
 SG_ TargetAngRateY: 16|16@1-  (0.01,0)  [-327.675|327.675]"°/s" Vector__XXX
 SG_ TargetAngRateZ: 32|16@1-  (0.01,0)  [-327.675|327.675]"°/s" Vector__XXX

BO_ 1801 TargetRateLevel: 6 RTRange
SG_ TargetAngRateForward:    0|16@1-  (0.01,0)  [-327.675|327.675]"°/s" Vector__XXX
SG_ TargetAngRateLateral:    16|16@1-  (0.01,0)  [-327.675|327.675]"°/s" Vector__XXX
SG_ TargetAngRateDown:       32|16@1-  (0.01,0)  [-327.675|327.675]"°/s" Vector__XXX

BO_ 1802 TargetTrackSlipCurvature: 8 RTRange
SG_ TargetAngleTrack: 0|16@1+  (0.01,0)  [0|655.35]"°" Vector__XXX
SG_ TargetAngleSlip: 16|16@1-  (0.01,0)  [-327.675|327.675]"°" Vector__XXX
SG_ TargetCurvature: 32|16@1-  (0.0001,0)  [-3.27675|3.27675]"1/m" Vector__XXX

BO_ 1804 TargetVelYawLocal: 8 RTRange
SG_ TargetVelLocalX:         0|16@1-  (0.01,0)  [-327.675|327.675]"m/s" Vector__XXX
SG_ TargetVelLocalY:         16|16@1-  (0.01,0)  [-327.675|327.675]"m/s" Vector__XXX
SG_ TargetAngleLocalYaw:     32|16@1-  (0.01,0)  [-327.675|327.675]"°" Vector__XXX
SG_ TargetAngleLocalTrack:   48|16@1-  (0.01,0)  [-327.675|327.675]"°" Vector__XXX

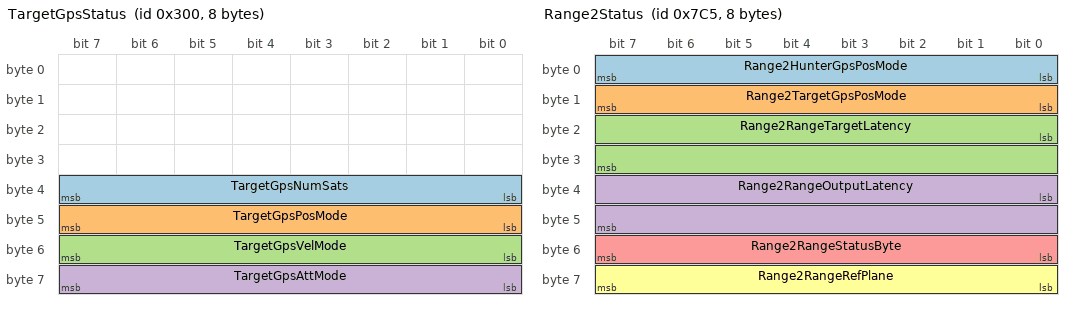
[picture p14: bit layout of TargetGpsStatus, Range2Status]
BO_ 768 TargetGpsStatus: 8 RTRange
SG_ TargetGpsNumSats: 32|8@1+  (1,0)  [0|255]"" Vector__XXX
SG_ TargetGpsPosMode: 40|8@1+  (1,0)  [0|255]"" Vector__XXX
SG_ TargetGpsVelMode: 48|8@1+  (1,0)  [0|255]"" Vector__XXX
SG_ TargetGpsAttMode: 56|8@1+  (1,0)  [0|255]"" Vector__XXX

BO_ 771 TargetPosNEDStdev: 8 RTRange
SG_ TargetPosNorthStdev: 0|16@1+  (0.001,0)  [0|65.535]"m" Vector__XXX
SG_ TargetPosEastStdev:  16|16@1+  (0.001,0)  [0|65.535]"m" Vector__XXX
SG_ TargetPosDownStdev:  32|16@1+  (0.001,0)  [0|65.535]"m" Vector__XXX

BO_ 772 TargetVelNEDStdev: 8 RTRange
SG_ TargetVelNorthStdev: 0|16@1+  (0.001,0)  [0|65.535]"m/s" Vector__XXX
SG_ TargetVelEastStdev:  16|16@1+  (0.001,0)  [0|65.535]"m/s" Vector__XXX
SG_ TargetVelDownStdev:  32|16@1+  (0.001,0)  [0|65.535]"m/s" Vector__XXX

BO_ 773 TargetAngleStdev: 8 RTRange
SG_ TargetAngleHeadingStdev: 0|16@1+  (0.000572958,0)  [0|37.54880253]"°" Vector__XXX
SG_ TargetAnglePitchStdev:   16|16@1+  (0.000572958,0)  [0|37.54880253]"°" Vector__XXX
SG_ TargetAngleRollStdev:    32|16@1+  (0.000572958,0)  [0|37.54880253]"°" Vector__XXX

BO_ 774 TargetGyroBias: 8 RTRange
SG_ TargetGyroBias1:    0|16@1-  (0.000286479,0)  [-9.3872006325|9.3872006325]"°/s" Vector__XXX
SG_ TargetGyroBias2:    16|16@1-  (0.000286479,0)  [-9.3872006325|9.3872006325]"°/s" Vector__XXX
SG_ TargetGyroBias3:    32|16@1-  (0.000286479,0)  [-9.3872006325|9.3872006325]"°/s" Vector__XXX

BO_ 775 TargetAccelBias: 8 RTRange
SG_ TargetAccelBias1:    0|16@1-  (0.0001,0)  [-3.27675|3.27675]"m/s²" Vector__XXX
SG_ TargetAccelBias2:    16|16@1-  (0.0001,0)  [-3.27675|3.27675]"m/s²" Vector__XXX
SG_ TargetAccelBias3:    32|16@1-  (0.0001,0)  [-3.27675|3.27675]"m/s²" Vector__XXX

BO_ 776 TargetGyroSf: 8 RTRange
SG_ TargetGyroSf1:    0|16@1-  (0.0002864788976,0)  [-9.387197277108|9.387197277108]"°/s" Vector__XXX
SG_ TargetGyroSf2:    16|16@1-  (0.0002864788976,0)  [-9.387197277108|9.387197277108]"°/s" Vector__XXX
SG_ TargetGyroSf3:    32|16@1-  (0.0002864788976,0)  [-9.387197277108|9.387197277108]"°/s" Vector__XXX

BO_ 777 TargetGyroBiasStdev: 8 RTRange
SG_ TargetGyroBias1Stdev:    0|16@1+  (5.729577951E-05,0)  [0|3.75487891018785]"°/s" Vector__XXX
SG_ TargetGyroBias2Stdev:    16|16@1+  (5.729577951E-05,0)  [0|3.75487891018785]"°/s" Vector__XXX
SG_ TargetGyroBias3Stdev:    32|16@1+  (5.729577951E-05,0)  [0|3.75487891018785]"°/s" Vector__XXX

BO_ 778 TargetAccelBiasStdev: 8 RTRange
SG_ TargetAccelBias1Stdev:    0|16@1-  (1E-05,0)  [-0.327675|0.327675]"m/s²" Vector__XXX
SG_ TargetAccelBias2Stdev:    16|16@1-  (1E-05,0)  [-0.327675|0.327675]"m/s²" Vector__XXX
SG_ TargetAccelBias3Stdev:    32|16@1-  (1E-05,0)  [-0.327675|0.327675]"m/s²" Vector__XXX

BO_ 779 TargetGyroSfStdev: 8 RTRange
SG_ TargetGyroSf1Stdev:  0|16@1+  (1E-05,0)  [0|0.65535]"m/s²" Vector__XXX
SG_ TargetGyroSf2Stdev:  16|16@1+  (1E-05,0)  [0|0.65535]"m/s²" Vector__XXX
SG_ TargetGyroSf3Stdev:  32|16@1+  (1E-05,0)  [0|0.65535]"m/s²" Vector__XXX

BO_ 780 TargetGpsAntOffset: 8 RTRange
SG_ TargetGpsAntX:  0|16@1-  (0.001,0)  [-32.7675|32.7675]"m" Vector__XXX
SG_ TargetGpsAntY:  16|16@1-  (0.001,0)  [-32.7675|32.7675]"m" Vector__XXX
SG_ TargetGpsAntZ:  32|16@1-  (0.001,0)  [-32.7675|32.7675]"m" Vector__XXX

BO_ 781 TargetGpsAntAngles: 8 RTRange
SG_ TargetGpsAntHeading:  0|16@1+  (0.005729578,0)  [0|375.48789423]"°" Vector__XXX
SG_ TargetGpsAntPitch:   16|16@1+  (0.005729578,0)  [0|375.48789423]"°" Vector__XXX

BO_ 782 TargetGpsAntStdev: 8 RTRange
SG_ TargetGpsAntXStdev: 0|16@1+  (0.0001,0)  [0|6.5535]"m" Vector__XXX
SG_ TargetGpsAntYStdev: 16|16@1+  (0.0001,0)  [0|6.5535]"m" Vector__XXX
SG_ TargetGpsAntZStdev: 32|16@1+  (0.0001,0)  [0|6.5535]"m" Vector__XXX

BO_ 783 TargetGpsAntAngleStdev: 8 RTRange
SG_ TargetGpsAntHeadingStdev:    0|16@1+  (0.000572958,0)  [0|37.54880253]"°" Vector__XXX
SG_ TargetGpsAntPitchStdev:      16|16@1+  (0.000572958,0)  [0|37.54880253]"°" Vector__XXX

BO_ 788 TargetGpsDiffAge: 8 RTRange
SG_ TargetGpsDiffAge: 0|16@1+  (0.01,0)  [0|655.35]"s" Vector__XXX

BO_ 816 TargetUndulationDOP: 8 RTRange
SG_ TargetUndulation: 0|16@1-  (0.005,0)  [-163.8375|163.8375]"m" Vector__XXX
SG_ TargetHDOP: 16|8@1+  (0.1,0)  [0|25.5]"" Vector__XXX
SG_ TargetPDOP: 24|8@1+  (0.1,0)  [0|25.5]"" Vector__XXX

BO_ 817 TargetTargetOmnistarTracking: 8 RTRange
SG_ TargetOmniSatFreq: 0|16@1+  (0.001,0)  [0|65.535]"MHz" Vector__XXX
SG_ TargetOmniSNR: 16|8@1+  (0.2,0)  [0|51]"dB" Vector__XXX
SG_ TargetOmniTrackTime: 24|8@1+  (1,0)  [0|255]"s" Vector__XXX

BO_ 1984  Range2Forward: 8 RTRange
SG_ Range2PosForward:             0|32@1-  (0.001,0)  [-2147483.6475|2147483.6475]"m" Vector__XXX
SG_ Range2VelForward:             32|16@1-  (0.01,0)  [-327.675|327.675]"m/s" Vector__XXX
SG_ Range2TimeToCollisionForward: 48|16@1-  (0.001,0)  [-32.7675|32.7675]"s" Vector__XXX

BO_ 1985 Range2Lateral: 8 RTRange
SG_ Range2PosLateral:             0|32@1-  (0.001,0)  [-2147483.6475|2147483.6475]"m" Vector__XXX
SG_ Range2VelLateral:             32|16@1-  (0.01,0)  [-327.675|327.675]"m/s" Vector__XXX
SG_ Range2TimeToCollisionLateral: 48|16@1-  (0.001,0)  [-32.7675|32.7675]"s" Vector__XXX

BO_ 1986 Range2Resultant: 8 RTRange
SG_ Range2PosRes:         0|32@1-  (0.001,0)  [-2147483.6475|2147483.6475]"m" Vector__XXX
SG_ Range2VelRes:         32|16@1-  (0.01,0)  [-327.675|327.675]"m/s" Vector__XXX
SG_ Range2AngleHeading:   48|16@1-  (0.01,0)  [-327.675|327.675]"°" Vector__XXX

BO_ 1987 Range2HunterPosLocal: 8 RTRange
SG_ Range2HunterPosLocalX : 0|32@1-  (0.001,0)  [-2147483.6475|2147483.6475]"m" Vector__XXX
SG_ Range2HunterPosLocalY : 32|32@1-  (0.001,0)  [-2147483.6475|2147483.6475]"m" Vector__XXX

BO_ 1988 Range2TargetPosLocal: 8 RTRange
SG_ Range2TargetPosLocalX: 0|32@1-  (0.001,0)  [-2147483.6475|2147483.6475]"m" Vector__XXX
SG_ Range2TargetPosLocalY: 32|32@1-  (0.001,0)  [-2147483.6475|2147483.6475]"m" Vector__XXX

BO_ 1989 Range2Status: 8 RTRange
SG_ Range2HunterGpsPosMode:       0|8@1+  (1,0)  [0|255]"" Vector__XXX
SG_ Range2TargetGpsPosMode:       8|8@1+  (1,0)  [0|255]"" Vector__XXX
SG_ Range2RangeTargetLatency:     16|16@1+  (0.001,0)  [0|65.535]"s" Vector__XXX
SG_ Range2RangeOutputLatency:     32|16@1+  (0.001,0)  [0|65.535]"s" Vector__XXX
SG_ Range2RangeStatusByte:        48|8@1+  (1,0)  [0|255]"" Vector__XXX
SG_ Range2RangeRefPlane:          56|8@1+  (1,0)  [0|255]"" Vector__XXX

BO_ 1990 Range2TimeGap: 4 RTRange
SG_  Range2TimeGap:                          0|16@1-  (0.001,0)  [-32.7675|32.7675]"s" Vector__XXX
SG_  Range2TimeToCollisionForwardWithAccel:  16|16@1-  (0.001,0)  [-32.7675|32.7675]"s" Vector__XXX

BO_ 1991 Range2Local: 8 RTRange
SG_ Range2LocalDeltaX:    0|32@1-  (0.001,0)  [-2147483.6475|2147483.6475]"m" Vector__XXX
SG_ Range2LocalDeltaY:    32|32@1-  (0.001,0)  [-2147483.6475|2147483.6475]"m" Vector__XXX

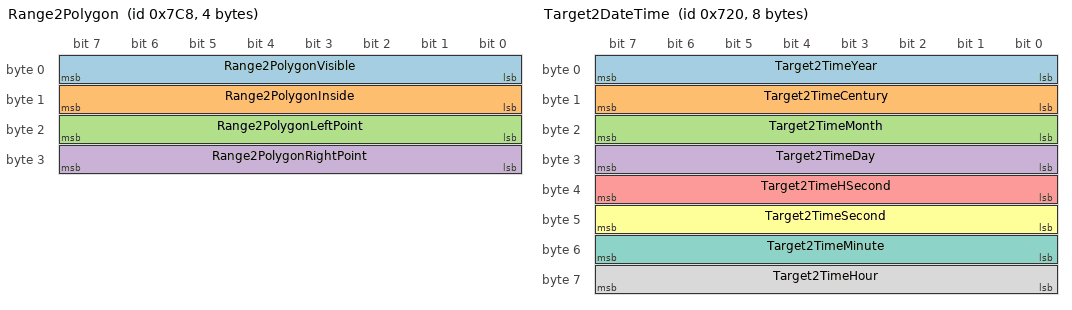
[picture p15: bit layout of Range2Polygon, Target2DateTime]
BO_ 1992 Range2Polygon: 4 RTRange
SG_ Range2PolygonVisible      : 0|8@1+  (1,0)  [0|255]"" Vector__XXX
SG_ Range2PolygonInside       : 8|8@1+  (1,0)  [0|255]"" Vector__XXX
SG_ Range2PolygonLeftPoint    : 16|8@1+  (1,0)  [0|255]"" Vector__XXX
SG_ Range2PolygonRightPoint   : 24|8@1+  (1,0)  [0|255]"" Vector__XXX

BO_ 1993 Range2FeatInfo: 4 RTRange
SG_ Range2FeatID      : 0|16@1+  (1,0)  [0|65535]"" Vector__XXX
SG_ Range2FeatType    : 16|8@1+  (1,0)  [0|255]"" Vector__XXX

BO_ 1824 Target2DateTime: 8 RTRange
SG_ Target2TimeYear:      0|8@1+  (1,0)  [0|255]"" Vector__XXX
SG_ Target2TimeCentury:   8|8@1+  (1,0)  [0|255]"" Vector__XXX
SG_ Target2TimeMonth:     16|8@1+  (1,0)  [0|255]"" Vector__XXX
SG_ Target2TimeDay:       24|8@1+  (1,0)  [0|255]"" Vector__XXX
SG_ Target2TimeHSecond:   32|8@1+  (0.01,0)  [0|2.55]"s" Vector__XXX
SG_ Target2TimeSecond:    40|8@1+  (1,0)  [0|255]"s" Vector__XXX
SG_ Target2TimeMinute:    48|8@1+  (1,0)  [0|255]"min" Vector__XXX
SG_ Target2TimeHour:      56|8@1+  (1,0)  [0|255]"hr" Vector__XXX

BO_ 1825 Target2LatitudeLongitude: 8 RTRange
SG_ Target2PosLat: 0|32@1-  (1E-07,0)  [-214.74836475|214.74836475]"°" Vector__XXX
SG_ Target2PosLon: 32|32@1-  (1E-07,0)  [-214.74836475|214.74836475]"°" Vector__XXX

BO_ 1826 Target2Altitude: 4 RTRange
SG_ Target2PosAlt: 0|32@1-  (0.001,0)  [-2147483.6475|2147483.6475]"m" Vector__XXX

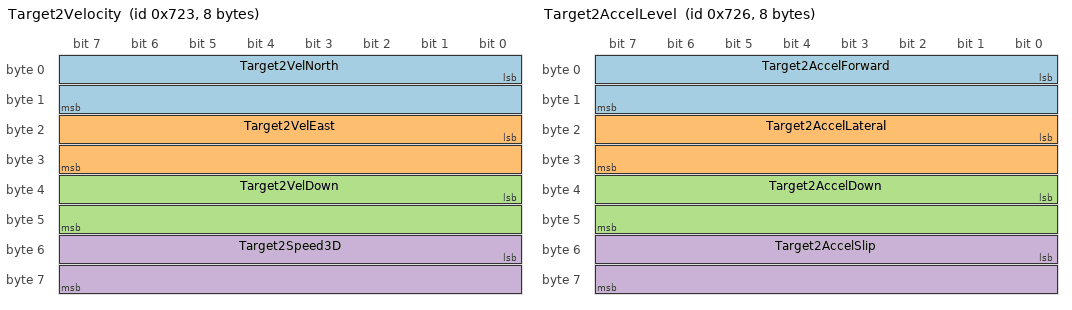
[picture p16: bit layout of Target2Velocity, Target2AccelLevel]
BO_ 1827 Target2Velocity: 8 RTRange
SG_ Target2VelNorth: 0|16@1-  (0.01,0)  [-327.675|327.675]"m/s" Vector__XXX
SG_ Target2VelEast: 16|16@1-  (0.01,0)  [-327.675|327.675]"m/s" Vector__XXX
SG_ Target2VelDown: 32|16@1-  (0.01,0)  [-327.675|327.675]"m/s" Vector__XXX
SG_ Target2Speed3D : 48|16@1+  (0.01,0)  [0|655.35]"m/s" Vector__XXX

BO_ 1828 Target2VelocityLevel: 4 RTRange
SG_ Target2VelForward: 0|16@1-  (0.01,0)  [-327.675|327.675]"m/s" Vector__XXX
SG_ Target2VelLateral: 16|16@1-  (0.01,0)  [-327.675|327.675]"m/s" Vector__XXX

BO_ 1829 Target2AccelVehicle: 6 RTRange
SG_ Target2AccelX : 0|16@1-  (0.01,0)  [-327.675|327.675]"m/s²" Vector__XXX
SG_ Target2AccelY : 16|16@1-  (0.01,0)  [-327.675|327.675]"m/s²" Vector__XXX
SG_ Target2AccelZ : 32|16@1-  (0.01,0)  [-327.675|327.675]"m/s²" Vector__XXX

BO_ 1830 Target2AccelLevel: 8 RTRange
SG_ Target2AccelForward:  0|16@1-  (0.01,0)  [-327.675|327.675]"m/s²" Vector__XXX
SG_ Target2AccelLateral:  16|16@1-  (0.01,0)  [-327.675|327.675]"m/s²" Vector__XXX
SG_ Target2AccelDown:     32|16@1-  (0.01,0)  [-327.675|327.675]"m/s²" Vector__XXX
SG_ Target2AccelSlip:     48|16@1-  (0.01,0)  [-327.675|327.675]"m/s²" Vector__XXX

BO_ 1831 Target2HeadingPitchRoll: 6 RTRange
 SG_ Target2AngleHeading: 0|16@1+  (0.01,0)  [0|655.35]"°" Vector__XXX
 SG_ Target2AnglePitch:   16|16@1-  (0.01,0)  [-327.675|327.675]"°" Vector__XXX
 SG_ Target2AngleRoll:    32|16@1-  (0.01,0)  [-327.675|327.675]"°" Vector__XXX

BO_ 1832 Target2RateVehicle: 6 RTRange
SG_ Target2AngRateX : 0|16@1-  (0.01,0)  [-327.675|327.675]"°/s" Vector__XXX
 SG_ Target2AngRateY: 16|16@1-  (0.01,0)  [-327.675|327.675]"°/s" Vector__XXX
 SG_ Target2AngRateZ: 32|16@1-  (0.01,0)  [-327.675|327.675]"°/s" Vector__XXX

BO_ 1833 Target2RateLevel: 6 RTRange
SG_ Target2AngRateForward:    0|16@1-  (0.01,0)  [-327.675|327.675]"°/s" Vector__XXX
SG_ Target2AngRateLateral:    16|16@1-  (0.01,0)  [-327.675|327.675]"°/s" Vector__XXX
SG_ Target2AngRateDown:       32|16@1-  (0.01,0)  [-327.675|327.675]"°/s" Vector__XXX

BO_ 1834 Target2TrackSlipCurvature: 8 RTRange
SG_ Target2AngleTrack: 0|16@1+  (0.01,0)  [0|655.35]"°" Vector__XXX
SG_ Target2AngleSlip: 16|16@1-  (0.01,0)  [-327.675|327.675]"°" Vector__XXX
SG_ Target2Curvature: 32|16@1-  (0.0001,0)  [-3.27675|3.27675]"1/m" Vector__XXX

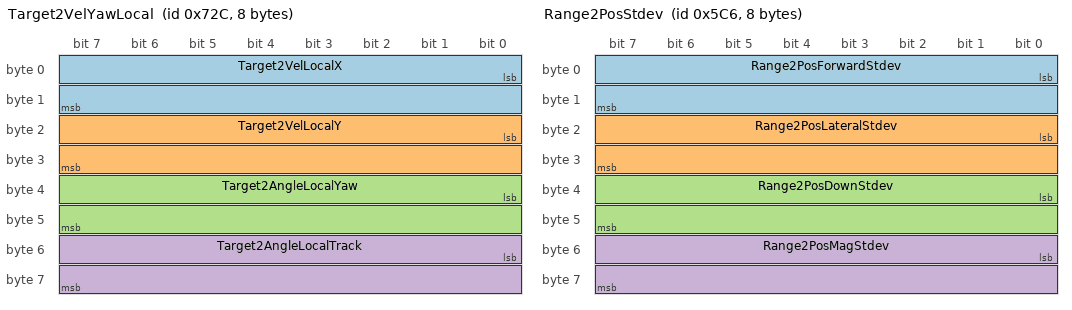
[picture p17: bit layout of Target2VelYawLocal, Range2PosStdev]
BO_ 1836 Target2VelYawLocal: 8 RTRange
SG_ Target2VelLocalX:         0|16@1-  (0.01,0)  [-327.675|327.675]"m/s" Vector__XXX
SG_ Target2VelLocalY:         16|16@1-  (0.01,0)  [-327.675|327.675]"m/s" Vector__XXX
SG_ Target2AngleLocalYaw:     32|16@1-  (0.01,0)  [-327.675|327.675]"°" Vector__XXX
SG_ Target2AngleLocalTrack:   48|16@1-  (0.01,0)  [-327.675|327.675]"°" Vector__XXX

BO_ 896 Target2GpsStatus: 4 RTRange
SG_ Target2GpsNumSats: 32|8@1+  (1,0)  [0|255]"" Vector__XXX
SG_ Target2GpsPosMode: 40|8@1+  (1,0)  [0|255]"" Vector__XXX
SG_ Target2GpsVelMode: 48|8@1+  (1,0)  [0|255]"" Vector__XXX
SG_ Target2GpsAttMode: 56|8@1+  (1,0)  [0|255]"" Vector__XXX

BO_ 899 Target2PosNEDStdev: 8 RTRange
SG_ Target2PosNorthStdev: 0|16@1+  (0.001,0)  [0|65.535]"m" Vector__XXX
SG_ Target2PosEastStdev:  16|16@1+  (0.001,0)  [0|65.535]"m" Vector__XXX
SG_ Target2PosDownStdev:  32|16@1+  (0.001,0)  [0|65.535]"m" Vector__XXX

BO_ 900 Target2VelNEDStdev: 8 RTRange
SG_ Target2VelNorthStdev: 0|16@1+  (0.001,0)  [0|65.535]"m/s" Vector__XXX
SG_ Target2VelEastStdev:  16|16@1+  (0.001,0)  [0|65.535]"m/s" Vector__XXX
SG_ Target2VelDownStdev:  32|16@1+  (0.001,0)  [0|65.535]"m/s" Vector__XXX

BO_ 901 Target2AngleStdev: 8 RTRange
SG_ Target2AngleHeadingStdev: 0|16@1+  (0.000572958,0)  [0|37.54880253]"°" Vector__XXX
SG_ Target2AnglePitchStdev:   16|16@1+  (0.000572958,0)  [0|37.54880253]"°" Vector__XXX
SG_ Target2AngleRollStdev:    32|16@1+  (0.000572958,0)  [0|37.54880253]"°" Vector__XXX

BO_ 902 Target2GyroBias: 8 RTRange
SG_ Target2GyroBias1:    0|16@1-  (0.000286479,0)  [-9.3872006325|9.3872006325]"°/s" Vector__XXX
SG_ Target2GyroBias2:    16|16@1-  (0.000286479,0)  [-9.3872006325|9.3872006325]"°/s" Vector__XXX
SG_ Target2GyroBias3:    32|16@1-  (0.000286479,0)  [-9.3872006325|9.3872006325]"°/s" Vector__XXX

BO_ 903 Target2AccelBias: 8 RTRange
SG_ Target2AccelBias1:    0|16@1-  (0.0001,0)  [-3.27675|3.27675]"m/s²" Vector__XXX
SG_ Target2AccelBias2:    16|16@1-  (0.0001,0)  [-3.27675|3.27675]"m/s²" Vector__XXX
SG_ Target2AccelBias3:    32|16@1-  (0.0001,0)  [-3.27675|3.27675]"m/s²" Vector__XXX

BO_ 904 Target2GyroSf: 8 RTRange
SG_ Target2GyroSf1:    0|16@1-  (0.0002864788976,0)  [-9.387197277108|9.387197277108]"°/s" Vector__XXX
SG_ Target2GyroSf2:    16|16@1-  (0.0002864788976,0)  [-9.387197277108|9.387197277108]"°/s" Vector__XXX
SG_ Target2GyroSf3:    32|16@1-  (0.0002864788976,0)  [-9.387197277108|9.387197277108]"°/s" Vector__XXX

BO_ 905 Target2GyroBiasStdev: 8 RTRange
SG_ Target2GyroBias1Stdev:    0|16@1+  (5.729577951E-05,0)  [0|3.75487891018785]"°/s" Vector__XXX
SG_ Target2GyroBias2Stdev:    16|16@1+  (5.729577951E-05,0)  [0|3.75487891018785]"°/s" Vector__XXX
SG_ Target2GyroBias3Stdev:    32|16@1+  (5.729577951E-05,0)  [0|3.75487891018785]"°/s" Vector__XXX

BO_ 906 Target2AccelBiasStdev: 8 RTRange
SG_ Target2AccelBias1Stdev:    0|16@1-  (1E-05,0)  [-0.327675|0.327675]"m/s²" Vector__XXX
SG_ Target2AccelBias2Stdev:    16|16@1-  (1E-05,0)  [-0.327675|0.327675]"m/s²" Vector__XXX
SG_ Target2AccelBias3Stdev:    32|16@1-  (1E-05,0)  [-0.327675|0.327675]"m/s²" Vector__XXX

BO_ 907 Target2GyroSfStdev: 8 RTRange
SG_ Target2GyroSf1Stdev:  0|16@1+  (1E-05,0)  [0|0.65535]"m/s²" Vector__XXX
SG_ Target2GyroSf2Stdev:  16|16@1+  (1E-05,0)  [0|0.65535]"m/s²" Vector__XXX
SG_ Target2GyroSf3Stdev:  32|16@1+  (1E-05,0)  [0|0.65535]"m/s²" Vector__XXX

BO_ 908 Target2GpsAntOffset: 8 RTRange
SG_ Target2GpsAntX:  0|16@1-  (0.001,0)  [-32.7675|32.7675]"m" Vector__XXX
SG_ Target2GpsAntY:  16|16@1-  (0.001,0)  [-32.7675|32.7675]"m" Vector__XXX
SG_ Target2GpsAntZ:  32|16@1-  (0.001,0)  [-32.7675|32.7675]"m" Vector__XXX

BO_ 909 Target2GpsAntAngles: 8 RTRange
SG_ Target2GpsAntHeading:  0|16@1+  (0.005729578,0)  [0|375.48789423]"°" Vector__XXX
SG_ Target2GpsAntPitch:   16|16@1+  (0.005729578,0)  [0|375.48789423]"°" Vector__XXX

BO_ 910 Target2GpsAntStdev: 8 RTRange
SG_ Target2GpsAntXStdev: 0|16@1+  (0.0001,0)  [0|6.5535]"m" Vector__XXX
SG_ Target2GpsAntYStdev: 16|16@1+  (0.0001,0)  [0|6.5535]"m" Vector__XXX
SG_ Target2GpsAntZStdev: 32|16@1+  (0.0001,0)  [0|6.5535]"m" Vector__XXX

BO_ 911 Target2GpsAntAngleStdev: 8 RTRange
SG_ Target2GpsAntHeadingStdev:    0|16@1+  (0.000572958,0)  [0|37.54880253]"°" Vector__XXX
SG_ Target2GpsAntPitchStdev:      16|16@1+  (0.000572958,0)  [0|37.54880253]"°" Vector__XXX

BO_ 916 Target2GpsDiffAge: 8 RTRange
SG_ Target2GpsDiffAge: 0|16@1+  (0.01,0)  [0|655.35]"s" Vector__XXX

BO_ 944 Target2UndulationDOP: 8 RTRange
SG_ Target2Undulation: 0|16@1-  (0.005,0)  [-163.8375|163.8375]"m" Vector__XXX
SG_ Target2HDOP: 16|8@1+  (0.1,0)  [0|25.5]"" Vector__XXX
SG_ Target2PDOP: 24|8@1+  (0.1,0)  [0|25.5]"" Vector__XXX

BO_ 945 Target2TargetOmnistarTracking: 8 RTRange
SG_ Target2OmniSatFreq: 0|16@1+  (0.001,0)  [0|65.535]"MHz" Vector__XXX
SG_ Target2OmniSNR: 16|8@1+  (0.2,0)  [0|51]"dB" Vector__XXX
SG_ Target2OmniTrackTime: 24|8@1+  (1,0)  [0|255]"s" Vector__XXX

BO_ 1472 Range2Offset: 8 RTRange
SG_ Range2OffsetForward:  0|16@1+  (0.001,0)  [0|65.535]"m" Vector__XXX
SG_ Range2OffsetLateral: 16|16@1+  (0.001,0)  [0|65.535]"m" Vector__XXX

BO_ 1473 Range2FixedPointLL: 8 RTRange
SG_ Range2FixedPointLat:  0|32@1-  (1E-07,0)  [-214.74836475|214.74836475]"°" Vector__XXX
SG_ Range2FixedPointLon:  32|32@1-  (1E-07,0)  [-214.74836475|214.74836475]"°" Vector__XXX

BO_ 1474 Range2FixedPointHH: 8 RTRange
SG_ Range2FixedPointAlt:  0|32@1-  (0.001,0)  [-2147483.6475|2147483.6475]"m" Vector__XXX
SG_ Range2FixedPointHea:  32|16@1+  (0.01,0)  [0|655.35]"m" Vector__XXX

BO_ 1475 Range2SensorLeverArm: 8 RTRange
SG_ Range2SensorLeverArmX: 0|16@1-  (0.001,0)  [-32.7675|32.7675]"m" Vector__XXX
SG_ Range2SensorLeverArmY: 16|16@1-  (0.001,0)  [-32.7675|32.7675]"m" Vector__XXX
SG_ Range2SensorLeverArmZ: 32|16@1-  (0.001,0)  [-32.7675|32.7675]"m" Vector__XXX

BO_ 1476 Range2BullsEyeLeverArm: 8 RTRange
SG_ Range2BullsEyeLeverArmX: 0|16@1-  (0.001,0)  [-32.7675|32.7675]"m" Vector__XXX
SG_ Range2BullsEyeLeverArmY: 16|16@1-  (0.001,0)  [-32.7675|32.7675]"m" Vector__XXX
SG_ Range2BullsEyeLeverArmZ: 32|16@1-  (0.001,0)  [-32.7675|32.7675]"m" Vector__XXX

BO_ 1477 Range2Vehicle: 8 RTRange
SG_ Range2TargetVehicleLength: 0|16@1+  (0.001,0)  [0|65.535]"m" Vector__XXX
SG_ Range2TargetVehicleWidth: 16|16@1+  (0.001,0)  [0|65.535]"m" Vector__XXX
SG_ Range2TargetPolygonNumber: 32|16@1+  (1,0)  [0|65535]"" Vector__XXX

BO_ 1478 Range2PosStdev: 8 RTRange
SG_ Range2PosForwardStdev: 0|16@1+  (0.001,0)  [0|65.535]"m" Vector__XXX
SG_ Range2PosLateralStdev: 16|16@1+  (0.001,0)  [0|65.535]"m" Vector__XXX
SG_ Range2PosDownStdev: 32|16@1+  (0.001,0)  [0|65.535]"m" Vector__XXX
SG_ Range2PosMagStdev: 48|16@1+  (0.001,0)  [0|65.535]"m" Vector__XXX

BO_ 1479 Range2FeatPointLL: 8 RTRange
SG_ Range2FeatPointLat: 0|32@1-  (1E-07,0)  [-214.74836475|214.74836475]"°" Vector__XXX
SG_ Range2FeatPointLon: 32|32@1-  (1E-07,0)  [-214.74836475|214.74836475]"°" Vector__XXX

BO_ 1480 Range2FeatPointHH: 8 RTRange
SG_ Range2FeatPointAlt: 0|32@1-  (0.001,0)  [-2147483.6475|2147483.6475]"m" Vector__XXX
SG_ Range2FeatPointHea: 32|16@1+  (0.01,0)  [0|655.35]"°" Vector__XXX

BO_ 2000  Range3Forward: 8 RTRange
SG_ Range3PosForward:             0|32@1-  (0.001,0)  [-2147483.6475|2147483.6475]"m" Vector__XXX
SG_ Range3VelForward:             32|16@1-  (0.01,0)  [-327.675|327.675]"m/s" Vector__XXX
SG_ Range3TimeToCollisionForward: 48|16@1-  (0.001,0)  [-32.7675|32.7675]"s" Vector__XXX

BO_ 2001 Range3Lateral: 8 RTRange
SG_ Range3PosLateral:             0|32@1-  (0.001,0)  [-2147483.6475|2147483.6475]"m" Vector__XXX
SG_ Range3VelLateral:             32|16@1-  (0.01,0)  [-327.675|327.675]"m/s" Vector__XXX
SG_ Range3TimeToCollisionLateral: 48|16@1-  (0.001,0)  [-32.7675|32.7675]"s" Vector__XXX

BO_ 2002 Range3Resultant: 8 RTRange
SG_ Range3PosRes:         0|32@1-  (0.001,0)  [-2147483.6475|2147483.6475]"m" Vector__XXX
SG_ Range3VelRes:         32|16@1-  (0.01,0)  [-327.675|327.675]"m/s" Vector__XXX
SG_ Range3AngleHeading:   48|16@1-  (0.01,0)  [-327.675|327.675]"°" Vector__XXX

BO_ 2003 Range3HunterPosLocal: 8 RTRange
SG_ Range3HunterPosLocalX : 0|32@1-  (0.001,0)  [-2147483.6475|2147483.6475]"m" Vector__XXX
SG_ Range3HunterPosLocalY : 32|32@1-  (0.001,0)  [-2147483.6475|2147483.6475]"m" Vector__XXX

BO_ 2004 Range3TargetPosLocal: 8 RTRange
SG_ Range3TargetPosLocalX: 0|32@1-  (0.001,0)  [-2147483.6475|2147483.6475]"m" Vector__XXX
SG_ Range3TargetPosLocalY: 32|32@1-  (0.001,0)  [-2147483.6475|2147483.6475]"m" Vector__XXX

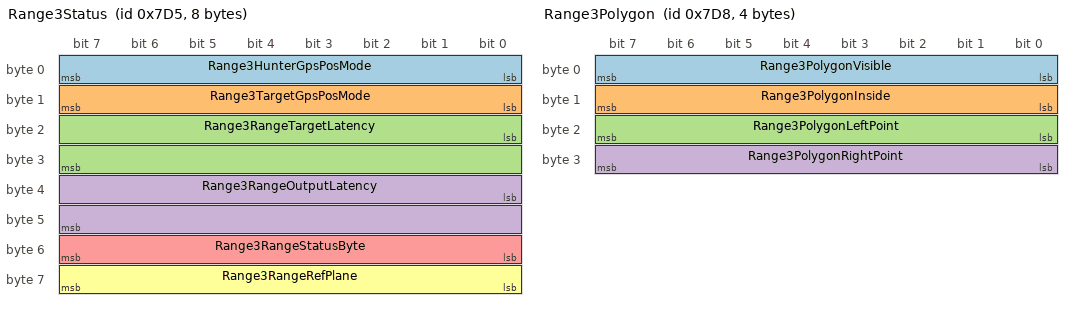
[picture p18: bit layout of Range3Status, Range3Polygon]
BO_ 2005 Range3Status: 8 RTRange
SG_ Range3HunterGpsPosMode:       0|8@1+  (1,0)  [0|255]"" Vector__XXX
SG_ Range3TargetGpsPosMode:       8|8@1+  (1,0)  [0|255]"" Vector__XXX
SG_ Range3RangeTargetLatency:     16|16@1+  (0.001,0)  [0|65.535]"s" Vector__XXX
SG_ Range3RangeOutputLatency:     32|16@1+  (0.001,0)  [0|65.535]"s" Vector__XXX
SG_ Range3RangeStatusByte:        48|8@1+  (1,0)  [0|255]"" Vector__XXX
SG_ Range3RangeRefPlane:          56|8@1+  (1,0)  [0|255]"" Vector__XXX

BO_ 2006 Range3TimeGap: 4 RTRange
SG_  Range3TimeGap:                          0|16@1-  (0.001,0)  [-32.7675|32.7675]"s" Vector__XXX
SG_  Range3TimeToCollisionForwardWithAccel:  16|16@1-  (0.001,0)  [-32.7675|32.7675]"s" Vector__XXX

BO_ 2007 Range3Local: 8 RTRange
SG_ Range3LocalDeltaX:    0|32@1-  (0.001,0)  [-2147483.6475|2147483.6475]"m" Vector__XXX
SG_ Range3LocalDeltaY:    32|32@1-  (0.001,0)  [-2147483.6475|2147483.6475]"m" Vector__XXX

BO_ 2008 Range3Polygon: 4 RTRange
SG_ Range3PolygonVisible      : 0|8@1+  (1,0)  [0|255]"" Vector__XXX
SG_ Range3PolygonInside       : 8|8@1+  (1,0)  [0|255]"" Vector__XXX
SG_ Range3PolygonLeftPoint    : 16|8@1+  (1,0)  [0|255]"" Vector__XXX
SG_ Range3PolygonRightPoint   : 24|8@1+  (1,0)  [0|255]"" Vector__XXX

BO_ 2009 Range3FeatInfo: 4 RTRange
SG_ Range3FeatID      : 0|16@1+  (1,0)  [0|65535]"" Vector__XXX
SG_ Range3FeatType    : 16|8@1+  (1,0)  [0|255]"" Vector__XXX

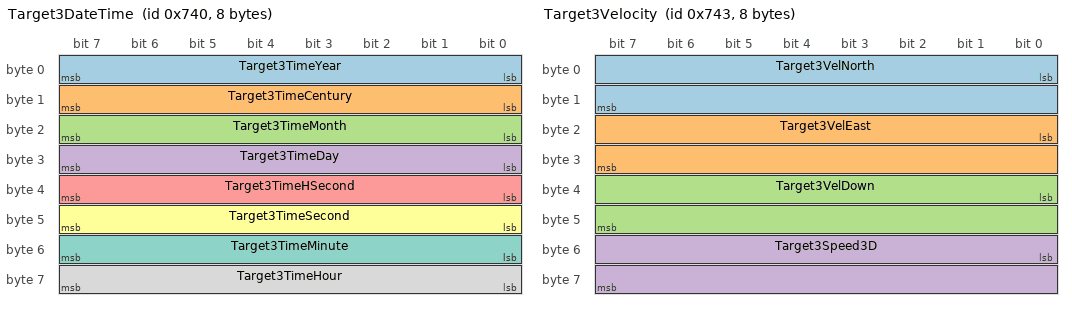
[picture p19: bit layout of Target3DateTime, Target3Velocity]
BO_ 1856 Target3DateTime: 8 RTRange
SG_ Target3TimeYear:      0|8@1+  (1,0)  [0|255]"" Vector__XXX
SG_ Target3TimeCentury:   8|8@1+  (1,0)  [0|255]"" Vector__XXX
SG_ Target3TimeMonth:     16|8@1+  (1,0)  [0|255]"" Vector__XXX
SG_ Target3TimeDay:       24|8@1+  (1,0)  [0|255]"" Vector__XXX
SG_ Target3TimeHSecond:   32|8@1+  (0.01,0)  [0|2.55]"s" Vector__XXX
SG_ Target3TimeSecond:    40|8@1+  (1,0)  [0|255]"s" Vector__XXX
SG_ Target3TimeMinute:    48|8@1+  (1,0)  [0|255]"min" Vector__XXX
SG_ Target3TimeHour:      56|8@1+  (1,0)  [0|255]"hr" Vector__XXX

BO_ 1857 Target3LatitudeLongitude: 8 RTRange
SG_ Target3PosLat: 0|32@1-  (1E-07,0)  [-214.74836475|214.74836475]"°" Vector__XXX
SG_ Target3PosLon: 32|32@1-  (1E-07,0)  [-214.74836475|214.74836475]"°" Vector__XXX

BO_ 1858 Target3Altitude: 4 RTRange
SG_ Target3PosAlt: 0|32@1-  (0.001,0)  [-2147483.6475|2147483.6475]"m" Vector__XXX

BO_ 1859 Target3Velocity: 8 RTRange
SG_ Target3VelNorth: 0|16@1-  (0.01,0)  [-327.675|327.675]"m/s" Vector__XXX
SG_ Target3VelEast: 16|16@1-  (0.01,0)  [-327.675|327.675]"m/s" Vector__XXX
SG_ Target3VelDown: 32|16@1-  (0.01,0)  [-327.675|327.675]"m/s" Vector__XXX
SG_ Target3Speed3D : 48|16@1+  (0.01,0)  [0|655.35]"m/s" Vector__XXX

BO_ 1860 Target3VelocityLevel: 4 RTRange
SG_ Target3VelForward: 0|16@1-  (0.01,0)  [-327.675|327.675]"m/s" Vector__XXX
SG_ Target3VelLateral: 16|16@1-  (0.01,0)  [-327.675|327.675]"m/s" Vector__XXX

BO_ 1861 Target3AccelVehicle: 6 RTRange
SG_ Target3AccelX : 0|16@1-  (0.01,0)  [-327.675|327.675]"m/s²" Vector__XXX
SG_ Target3AccelY : 16|16@1-  (0.01,0)  [-327.675|327.675]"m/s²" Vector__XXX
SG_ Target3AccelZ : 32|16@1-  (0.01,0)  [-327.675|327.675]"m/s²" Vector__XXX

BO_ 1862 Target3AccelLevel: 8 RTRange
SG_ Target3AccelForward:  0|16@1-  (0.01,0)  [-327.675|327.675]"m/s²" Vector__XXX
SG_ Target3AccelLateral:  16|16@1-  (0.01,0)  [-327.675|327.675]"m/s²" Vector__XXX
SG_ Target3AccelDown:     32|16@1-  (0.01,0)  [-327.675|327.675]"m/s²" Vector__XXX
SG_ Target3AccelSlip:     48|16@1-  (0.01,0)  [-327.675|327.675]"m/s²" Vector__XXX

BO_ 1863 Target3HeadingPitchRoll: 6 RTRange
 SG_ Target3AngleHeading: 0|16@1+  (0.01,0)  [0|655.35]"°" Vector__XXX
 SG_ Target3AnglePitch:   16|16@1-  (0.01,0)  [-327.675|327.675]"°" Vector__XXX
 SG_ Target3AngleRoll:    32|16@1-  (0.01,0)  [-327.675|327.675]"°" Vector__XXX

BO_ 1864 Target3RateVehicle: 6 RTRange
SG_ Target3AngRateX : 0|16@1-  (0.01,0)  [-327.675|327.675]"°/s" Vector__XXX
 SG_ Target3AngRateY: 16|16@1-  (0.01,0)  [-327.675|327.675]"°/s" Vector__XXX
 SG_ Target3AngRateZ: 32|16@1-  (0.01,0)  [-327.675|327.675]"°/s" Vector__XXX

BO_ 1865 Target3RateLevel: 6 RTRange
SG_ Target3AngRateForward:    0|16@1-  (0.01,0)  [-327.675|327.675]"°/s" Vector__XXX
SG_ Target3AngRateLateral:    16|16@1-  (0.01,0)  [-327.675|327.675]"°/s" Vector__XXX
SG_ Target3AngRateDown:       32|16@1-  (0.01,0)  [-327.675|327.675]"°/s" Vector__XXX

BO_ 1866 Target3TrackSlipCurvature: 8 RTRange
SG_ Target3AngleTrack: 0|16@1+  (0.01,0)  [0|655.35]"°" Vector__XXX
SG_ Target3AngleSlip: 16|16@1-  (0.01,0)  [-327.675|327.675]"°" Vector__XXX
SG_ Target3Curvature: 32|16@1-  (0.0001,0)  [-3.27675|3.27675]"1/m" Vector__XXX

BO_ 1868 Target3VelYawLocal: 8 RTRange
SG_ Target3VelLocalX:         0|16@1-  (0.01,0)  [-327.675|327.675]"m/s" Vector__XXX
SG_ Target3VelLocalY:         16|16@1-  (0.01,0)  [-327.675|327.675]"m/s" Vector__XXX
SG_ Target3AngleLocalYaw:     32|16@1-  (0.01,0)  [-327.675|327.675]"°" Vector__XXX
SG_ Target3AngleLocalTrack:   48|16@1-  (0.01,0)  [-327.675|327.675]"°" Vector__XXX

BO_ 1024 Target3GpsStatus: 4 RTRange
SG_ Target3GpsNumSats: 32|8@1+  (1,0)  [0|255]"" Vector__XXX
SG_ Target3GpsPosMode: 40|8@1+  (1,0)  [0|255]"" Vector__XXX
SG_ Target3GpsVelMode: 48|8@1+  (1,0)  [0|255]"" Vector__XXX
SG_ Target3GpsAttMode: 56|8@1+  (1,0)  [0|255]"" Vector__XXX

BO_ 1027 Target3PosNEDStdev: 8 RTRange
SG_ Target3PosNorthStdev: 0|16@1+  (0.001,0)  [0|65.535]"m" Vector__XXX
SG_ Target3PosEastStdev:  16|16@1+  (0.001,0)  [0|65.535]"m" Vector__XXX
SG_ Target3PosDownStdev:  32|16@1+  (0.001,0)  [0|65.535]"m" Vector__XXX

BO_ 1028 Target3VelNEDStdev: 8 RTRange
SG_ Target3VelNorthStdev: 0|16@1+  (0.001,0)  [0|65.535]"m/s" Vector__XXX
SG_ Target3VelEastStdev:  16|16@1+  (0.001,0)  [0|65.535]"m/s" Vector__XXX
SG_ Target3VelDownStdev:  32|16@1+  (0.001,0)  [0|65.535]"m/s" Vector__XXX

BO_ 1029 Target3AngleStdev: 8 RTRange
SG_ Target3AngleHeadingStdev: 0|16@1+  (0.000572958,0)  [0|37.54880253]"°" Vector__XXX
SG_ Target3AnglePitchStdev:   16|16@1+  (0.000572958,0)  [0|37.54880253]"°" Vector__XXX
SG_ Target3AngleRollStdev:    32|16@1+  (0.000572958,0)  [0|37.54880253]"°" Vector__XXX

BO_ 1030 Target3GyroBias: 8 RTRange
SG_ Target3GyroBias1:    0|16@1-  (0.000286479,0)  [-9.3872006325|9.3872006325]"°/s" Vector__XXX
SG_ Target3GyroBias2:    16|16@1-  (0.000286479,0)  [-9.3872006325|9.3872006325]"°/s" Vector__XXX
SG_ Target3GyroBias3:    32|16@1-  (0.000286479,0)  [-9.3872006325|9.3872006325]"°/s" Vector__XXX

BO_ 1031 Target3AccelBias: 8 RTRange
SG_ Target3AccelBias1:    0|16@1-  (0.0001,0)  [-3.27675|3.27675]"m/s²" Vector__XXX
SG_ Target3AccelBias2:    16|16@1-  (0.0001,0)  [-3.27675|3.27675]"m/s²" Vector__XXX
SG_ Target3AccelBias3:    32|16@1-  (0.0001,0)  [-3.27675|3.27675]"m/s²" Vector__XXX

BO_ 1032 Target3GyroSf: 8 RTRange
SG_ Target3GyroSf1:    0|16@1-  (0.0002864788976,0)  [-9.387197277108|9.387197277108]"°/s" Vector__XXX
SG_ Target3GyroSf2:    16|16@1-  (0.0002864788976,0)  [-9.387197277108|9.387197277108]"°/s" Vector__XXX
SG_ Target3GyroSf3:    32|16@1-  (0.0002864788976,0)  [-9.387197277108|9.387197277108]"°/s" Vector__XXX

BO_ 1033 Target3GyroBiasStdev: 8 RTRange
SG_ Target3GyroBias1Stdev:    0|16@1+  (5.729577951E-05,0)  [0|3.75487891018785]"°/s" Vector__XXX
SG_ Target3GyroBias2Stdev:    16|16@1+  (5.729577951E-05,0)  [0|3.75487891018785]"°/s" Vector__XXX
SG_ Target3GyroBias3Stdev:    32|16@1+  (5.729577951E-05,0)  [0|3.75487891018785]"°/s" Vector__XXX

BO_ 1034 Target3AccelBiasStdev: 8 RTRange
SG_ Target3AccelBias1Stdev:    0|16@1-  (1E-05,0)  [-0.327675|0.327675]"m/s²" Vector__XXX
SG_ Target3AccelBias2Stdev:    16|16@1-  (1E-05,0)  [-0.327675|0.327675]"m/s²" Vector__XXX
SG_ Target3AccelBias3Stdev:    32|16@1-  (1E-05,0)  [-0.327675|0.327675]"m/s²" Vector__XXX

BO_ 1035 Target3GyroSfStdev: 8 RTRange
SG_ Target3GyroSf1Stdev:  0|16@1+  (1E-05,0)  [0|0.65535]"m/s²" Vector__XXX
SG_ Target3GyroSf2Stdev:  16|16@1+  (1E-05,0)  [0|0.65535]"m/s²" Vector__XXX
SG_ Target3GyroSf3Stdev:  32|16@1+  (1E-05,0)  [0|0.65535]"m/s²" Vector__XXX

BO_ 1036 Target3GpsAntOffset: 8 RTRange
SG_ Target3GpsAntX:  0|16@1-  (0.001,0)  [-32.7675|32.7675]"m" Vector__XXX
SG_ Target3GpsAntY:  16|16@1-  (0.001,0)  [-32.7675|32.7675]"m" Vector__XXX
SG_ Target3GpsAntZ:  32|16@1-  (0.001,0)  [-32.7675|32.7675]"m" Vector__XXX

BO_ 1037 Target3GpsAntAngles: 8 RTRange
SG_ Target3GpsAntHeading:  0|16@1+  (0.005729578,0)  [0|375.48789423]"°" Vector__XXX
SG_ Target3GpsAntPitch:   16|16@1+  (0.005729578,0)  [0|375.48789423]"°" Vector__XXX

BO_ 1038 Target3GpsAntStdev: 8 RTRange
SG_ Target3GpsAntXStdev: 0|16@1+  (0.0001,0)  [0|6.5535]"m" Vector__XXX
SG_ Target3GpsAntYStdev: 16|16@1+  (0.0001,0)  [0|6.5535]"m" Vector__XXX
SG_ Target3GpsAntZStdev: 32|16@1+  (0.0001,0)  [0|6.5535]"m" Vector__XXX

BO_ 1039 Target3GpsAntAngleStdev: 8 RTRange
SG_ Target3GpsAntHeadingStdev:    0|16@1+  (0.000572958,0)  [0|37.54880253]"°" Vector__XXX
SG_ Target3GpsAntPitchStdev:      16|16@1+  (0.000572958,0)  [0|37.54880253]"°" Vector__XXX

BO_ 1044 Target3GpsDiffAge: 8 RTRange
SG_ Target3GpsDiffAge: 0|16@1+  (0.01,0)  [0|655.35]"s" Vector__XXX

BO_ 1072 Target3UndulationDOP: 8 RTRange
SG_ Target3Undulation: 0|16@1-  (0.005,0)  [-163.8375|163.8375]"m" Vector__XXX
SG_ Target3HDOP: 16|8@1+  (0.1,0)  [0|25.5]"" Vector__XXX
SG_ Target3PDOP: 24|8@1+  (0.1,0)  [0|25.5]"" Vector__XXX

BO_ 1073 Target3TargetOmnistarTracking: 8 RTRange
SG_ Target3OmniSatFreq: 0|16@1+  (0.001,0)  [0|65.535]"MHz" Vector__XXX
SG_ Target3OmniSNR: 16|8@1+  (0.2,0)  [0|51]"dB" Vector__XXX
SG_ Target3OmniTrackTime: 24|8@1+  (1,0)  [0|255]"s" Vector__XXX

BO_ 1488 Range3Offset: 8 RTRange
SG_ Range3OffsetForward:  0|16@1+  (0.001,0)  [0|65.535]"m" Vector__XXX
SG_ Range3OffsetLateral: 16|16@1+  (0.001,0)  [0|65.535]"m" Vector__XXX

BO_ 1489 Range3FixedPointLL: 8 RTRange
SG_ Range3FixedPointLat:  0|32@1-  (1E-07,0)  [-214.74836475|214.74836475]"°" Vector__XXX
SG_ Range3FixedPointLon:  32|32@1-  (1E-07,0)  [-214.74836475|214.74836475]"°" Vector__XXX

BO_ 1490 Range3FixedPointHH: 8 RTRange
SG_ Range3FixedPointAlt:  0|32@1-  (0.001,0)  [-2147483.6475|2147483.6475]"m" Vector__XXX
SG_ Range3FixedPointHea:  32|16@1+  (0.01,0)  [0|655.35]"m" Vector__XXX

BO_ 1491 Range3SensorLeverArm: 8 RTRange
SG_ Range3SensorLeverArmX: 0|16@1-  (0.001,0)  [-32.7675|32.7675]"m" Vector__XXX
SG_ Range3SensorLeverArmY: 16|16@1-  (0.001,0)  [-32.7675|32.7675]"m" Vector__XXX
SG_ Range3SensorLeverArmZ: 32|16@1-  (0.001,0)  [-32.7675|32.7675]"m" Vector__XXX

BO_ 1492 Range3BullsEyeLeverArm: 8 RTRange
SG_ Range3BullsEyeLeverArmX: 0|16@1-  (0.001,0)  [-32.7675|32.7675]"m" Vector__XXX
SG_ Range3BullsEyeLeverArmY: 16|16@1-  (0.001,0)  [-32.7675|32.7675]"m" Vector__XXX
SG_ Range3BullsEyeLeverArmZ: 32|16@1-  (0.001,0)  [-32.7675|32.7675]"m" Vector__XXX

BO_ 1493 Range3Vehicle: 8 RTRange
SG_ Range3TargetVehicleLength: 0|16@1+  (0.001,0)  [0|65.535]"m" Vector__XXX
SG_ Range3TargetVehicleWidth: 16|16@1+  (0.001,0)  [0|65.535]"m" Vector__XXX
SG_ Range3TargetPolygonNumber: 32|16@1+  (1,0)  [0|65535]"" Vector__XXX

BO_ 1494 Range3PosStdev: 8 RTRange
SG_ Range3PosForwardStdev: 0|16@1+  (0.001,0)  [0|65.535]"m" Vector__XXX
SG_ Range3PosLateralStdev: 16|16@1+  (0.001,0)  [0|65.535]"m" Vector__XXX
SG_ Range3PosDownStdev: 32|16@1+  (0.001,0)  [0|65.535]"m" Vector__XXX
SG_ Range3PosMagStdev: 48|16@1+  (0.001,0)  [0|65.535]"m" Vector__XXX

BO_ 1495 Range3FeatPointLL: 8 RTRange
SG_ Range3FeatPointLat: 0|32@1-  (1E-07,0)  [-214.74836475|214.74836475]"°" Vector__XXX
SG_ Range3FeatPointLon: 32|32@1-  (1E-07,0)  [-214.74836475|214.74836475]"°" Vector__XXX

BO_ 1496 Range3FeatPointHH: 8 RTRange
SG_ Range3FeatPointAlt: 0|32@1-  (0.001,0)  [-2147483.6475|2147483.6475]"m" Vector__XXX
SG_ Range3FeatPointHea: 32|16@1+  (0.01,0)  [0|655.35]"°" Vector__XXX
